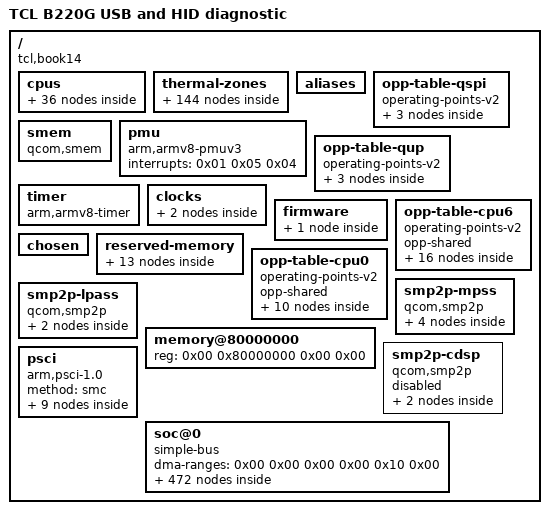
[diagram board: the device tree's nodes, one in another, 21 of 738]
/dts-v1/;

/ {
	model = "TCL B220G USB and HID diagnostic";
	compatible = "tcl,book14", "qcom,sc7180";
	interrupt-parent = <0x01>;
	#address-cells = <0x02>;
	#size-cells = <0x02>;

	cpus {
		#address-cells = <0x02>;
		#size-cells = <0x00>;

		cpu@600 {
			dynamic-power-coefficient = <0x1e0>;
			next-level-cache = <0x09>;
			clocks = <0xbb 0x01>;
			phandle = <0x11>;
			compatible = "qcom,kryo468";
			capacity-dmips-mhz = <0x400>;
			reg = <0x00 0x600>;
			device_type = "cpu";
			qcom,freq-domain = <0xbb 0x01>;
			enable-method = "psci";
			#cooling-cells = <0x02>;

			l2-cache {
				next-level-cache = <0x03>;
				phandle = <0x09>;
				compatible = "cache";
				cache-unified;
				cache-level = <0x02>;
			};
		};

		cpu@300 {
			dynamic-power-coefficient = <0x89>;
			next-level-cache = <0x06>;
			clocks = <0xbb 0x00>;
			phandle = <0x0e>;
			compatible = "qcom,kryo468";
			capacity-dmips-mhz = <0x19f>;
			reg = <0x00 0x300>;
			device_type = "cpu";
			qcom,freq-domain = <0xbb 0x00>;
			enable-method = "psci";
			#cooling-cells = <0x02>;

			l2-cache {
				next-level-cache = <0x03>;
				phandle = <0x06>;
				compatible = "cache";
				cache-unified;
				cache-level = <0x02>;
			};
		};

		cpu@0 {
			dynamic-power-coefficient = <0x89>;
			next-level-cache = <0x02>;
			clocks = <0xbb 0x00>;
			phandle = <0x0b>;
			compatible = "qcom,kryo468";
			capacity-dmips-mhz = <0x19f>;
			reg = <0x00 0x00>;
			device_type = "cpu";
			qcom,freq-domain = <0xbb 0x00>;
			enable-method = "psci";
			#cooling-cells = <0x02>;

			l2-cache {
				next-level-cache = <0x03>;
				phandle = <0x02>;
				compatible = "cache";
				cache-unified;
				cache-level = <0x02>;

				l3-cache {
					phandle = <0x03>;
					compatible = "cache";
					cache-unified;
					cache-level = <0x03>;
				};
			};
		};

		cpu@500 {
			dynamic-power-coefficient = <0x89>;
			next-level-cache = <0x08>;
			clocks = <0xbb 0x00>;
			phandle = <0x10>;
			compatible = "qcom,kryo468";
			capacity-dmips-mhz = <0x19f>;
			reg = <0x00 0x500>;
			device_type = "cpu";
			qcom,freq-domain = <0xbb 0x00>;
			enable-method = "psci";
			#cooling-cells = <0x02>;

			l2-cache {
				next-level-cache = <0x03>;
				phandle = <0x08>;
				compatible = "cache";
				cache-unified;
				cache-level = <0x02>;
			};
		};

		idle-states {
			entry-method = "psci";

			cpu-sleep-1-0 {
				min-residency-us = <0x89f>;
				exit-latency-us = <0x4dc>;
				phandle = <0x19>;
				compatible = "arm,idle-state";
				arm,psci-suspend-param = <0x40000003>;
				entry-latency-us = <0x20b>;
				local-timer-stop;
				idle-state-name = "big-power-down";
			};

			cpu-sleep-0-1 {
				min-residency-us = <0xfa1>;
				exit-latency-us = <0x393>;
				phandle = <0x18>;
				compatible = "arm,idle-state";
				arm,psci-suspend-param = <0x40000004>;
				entry-latency-us = <0x2be>;
				local-timer-stop;
				idle-state-name = "little-rail-power-down";
			};

			cpu-sleep-1-1 {
				min-residency-us = <0x15b3>;
				exit-latency-us = <0x73e>;
				phandle = <0x1a>;
				compatible = "arm,idle-state";
				arm,psci-suspend-param = <0x40000004>;
				entry-latency-us = <0x20e>;
				local-timer-stop;
				idle-state-name = "big-rail-power-down";
			};

			cpu-sleep-0-0 {
				min-residency-us = <0x6ee>;
				exit-latency-us = <0x385>;
				phandle = <0x17>;
				compatible = "arm,idle-state";
				arm,psci-suspend-param = <0x40000003>;
				entry-latency-us = <0x225>;
				local-timer-stop;
				idle-state-name = "little-power-down";
			};
		};

		cpu@400 {
			dynamic-power-coefficient = <0x89>;
			next-level-cache = <0x07>;
			clocks = <0xbb 0x00>;
			phandle = <0x0f>;
			compatible = "qcom,kryo468";
			capacity-dmips-mhz = <0x19f>;
			reg = <0x00 0x400>;
			device_type = "cpu";
			qcom,freq-domain = <0xbb 0x00>;
			enable-method = "psci";
			#cooling-cells = <0x02>;

			l2-cache {
				next-level-cache = <0x03>;
				phandle = <0x07>;
				compatible = "cache";
				cache-unified;
				cache-level = <0x02>;
			};
		};

		cpu@700 {
			dynamic-power-coefficient = <0x1e0>;
			next-level-cache = <0x0a>;
			clocks = <0xbb 0x01>;
			phandle = <0x12>;
			compatible = "qcom,kryo468";
			capacity-dmips-mhz = <0x400>;
			reg = <0x00 0x700>;
			device_type = "cpu";
			qcom,freq-domain = <0xbb 0x01>;
			enable-method = "psci";
			#cooling-cells = <0x02>;

			l2-cache {
				next-level-cache = <0x03>;
				phandle = <0x0a>;
				compatible = "cache";
				cache-unified;
				cache-level = <0x02>;
			};
		};

		cpu@200 {
			dynamic-power-coefficient = <0x89>;
			next-level-cache = <0x05>;
			clocks = <0xbb 0x00>;
			phandle = <0x0d>;
			compatible = "qcom,kryo468";
			capacity-dmips-mhz = <0x19f>;
			reg = <0x00 0x200>;
			device_type = "cpu";
			qcom,freq-domain = <0xbb 0x00>;
			enable-method = "psci";
			#cooling-cells = <0x02>;

			l2-cache {
				next-level-cache = <0x03>;
				phandle = <0x05>;
				compatible = "cache";
				cache-unified;
				cache-level = <0x02>;
			};
		};

		cpu@100 {
			dynamic-power-coefficient = <0x89>;
			next-level-cache = <0x04>;
			clocks = <0xbb 0x00>;
			phandle = <0x0c>;
			compatible = "qcom,kryo468";
			capacity-dmips-mhz = <0x19f>;
			reg = <0x00 0x100>;
			device_type = "cpu";
			qcom,freq-domain = <0xbb 0x00>;
			enable-method = "psci";
			#cooling-cells = <0x02>;

			l2-cache {
				next-level-cache = <0x03>;
				phandle = <0x04>;
				compatible = "cache";
				cache-unified;
				cache-level = <0x02>;
			};
		};

		cpu-map {

			cluster0 {

				core1 {
					cpu = <0x0c>;
				};

				core7 {
					cpu = <0x12>;
				};

				core4 {
					cpu = <0x0f>;
				};

				core3 {
					cpu = <0x0e>;
				};

				core2 {
					cpu = <0x0d>;
				};

				core5 {
					cpu = <0x10>;
				};

				core6 {
					cpu = <0x11>;
				};

				core0 {
					cpu = <0x0b>;
				};
			};
		};

		domain-idle-states {

			cluster-sleep-2 {
				min-residency-us = <0x2662>;
				exit-latency-us = <0x19a2>;
				phandle = <0x1d>;
				compatible = "domain-idle-state";
				arm,psci-suspend-param = <0x4100b244>;
				entry-latency-us = <0xcbf>;
			};

			cluster-sleep-1 {
				min-residency-us = <0x2113>;
				exit-latency-us = <0x11d2>;
				phandle = <0x1c>;
				compatible = "domain-idle-state";
				arm,psci-suspend-param = <0x41001244>;
				entry-latency-us = <0xe36>;
			};

			cluster-sleep-0 {
				min-residency-us = <0x17e6>;
				exit-latency-us = <0xbe8>;
				phandle = <0x1b>;
				compatible = "domain-idle-state";
				arm,psci-suspend-param = <0x41000044>;
				entry-latency-us = <0xac0>;
			};
		};
	};

	thermal-zones {

		cpu4-thermal {
			thermal-sensors = <0xc1 0x05>;
			polling-delay-passive = <0xfa>;
			sustainable-power = <0x41c>;

			cooling-maps {

				map0 {
					trip = <0xca>;
					cooling-device = <0x0b 0xffffffff 0xffffffff 0x0c 0xffffffff 0xffffffff 0x0d 0xffffffff 0xffffffff 0x0e 0xffffffff 0xffffffff 0x0f 0xffffffff 0xffffffff 0x10 0xffffffff 0xffffffff>;
				};

				map1 {
					trip = <0xcb>;
					cooling-device = <0x0b 0xffffffff 0xffffffff 0x0c 0xffffffff 0xffffffff 0x0d 0xffffffff 0xffffffff 0x0e 0xffffffff 0xffffffff 0x0f 0xffffffff 0xffffffff 0x10 0xffffffff 0xffffffff>;
				};
			};

			trips {

				trip-point1 {
					hysteresis = <0x7d0>;
					phandle = <0xcb>;
					temperature = <0x17318>;
					type = "passive";
				};

				trip-point0 {
					hysteresis = <0x7d0>;
					phandle = <0xca>;
					temperature = <0x15f90>;
					type = "passive";
				};

				cpu-crit {
					hysteresis = <0x3e8>;
					temperature = <0x1adb0>;
					type = "critical";
				};
			};
		};

		cpu5-thermal {
			thermal-sensors = <0xc1 0x06>;
			polling-delay-passive = <0xfa>;
			sustainable-power = <0x41c>;

			cooling-maps {

				map0 {
					trip = <0xcc>;
					cooling-device = <0x0b 0xffffffff 0xffffffff 0x0c 0xffffffff 0xffffffff 0x0d 0xffffffff 0xffffffff 0x0e 0xffffffff 0xffffffff 0x0f 0xffffffff 0xffffffff 0x10 0xffffffff 0xffffffff>;
				};

				map1 {
					trip = <0xcd>;
					cooling-device = <0x0b 0xffffffff 0xffffffff 0x0c 0xffffffff 0xffffffff 0x0d 0xffffffff 0xffffffff 0x0e 0xffffffff 0xffffffff 0x0f 0xffffffff 0xffffffff 0x10 0xffffffff 0xffffffff>;
				};
			};

			trips {

				trip-point1 {
					hysteresis = <0x7d0>;
					phandle = <0xcd>;
					temperature = <0x17318>;
					type = "passive";
				};

				trip-point0 {
					hysteresis = <0x7d0>;
					phandle = <0xcc>;
					temperature = <0x15f90>;
					type = "passive";
				};

				cpu-crit {
					hysteresis = <0x3e8>;
					temperature = <0x1adb0>;
					type = "critical";
				};
			};
		};

		cpu9-thermal {
			thermal-sensors = <0xc1 0x0c>;
			polling-delay-passive = <0xfa>;
			sustainable-power = <0x591>;

			cooling-maps {

				map0 {
					trip = <0xd4>;
					cooling-device = <0x11 0xffffffff 0xffffffff 0x12 0xffffffff 0xffffffff>;
				};

				map1 {
					trip = <0xd5>;
					cooling-device = <0x11 0xffffffff 0xffffffff 0x12 0xffffffff 0xffffffff>;
				};
			};

			trips {

				trip-point1 {
					hysteresis = <0x7d0>;
					phandle = <0xd5>;
					temperature = <0x17318>;
					type = "passive";
				};

				trip-point0 {
					hysteresis = <0x7d0>;
					phandle = <0xd4>;
					temperature = <0x15f90>;
					type = "passive";
				};

				cpu-crit {
					hysteresis = <0x3e8>;
					temperature = <0x1adb0>;
					type = "critical";
				};
			};
		};

		cpu2-thermal {
			thermal-sensors = <0xc1 0x03>;
			polling-delay-passive = <0xfa>;
			sustainable-power = <0x41c>;

			cooling-maps {

				map0 {
					trip = <0xc6>;
					cooling-device = <0x0b 0xffffffff 0xffffffff 0x0c 0xffffffff 0xffffffff 0x0d 0xffffffff 0xffffffff 0x0e 0xffffffff 0xffffffff 0x0f 0xffffffff 0xffffffff 0x10 0xffffffff 0xffffffff>;
				};

				map1 {
					trip = <0xc7>;
					cooling-device = <0x0b 0xffffffff 0xffffffff 0x0c 0xffffffff 0xffffffff 0x0d 0xffffffff 0xffffffff 0x0e 0xffffffff 0xffffffff 0x0f 0xffffffff 0xffffffff 0x10 0xffffffff 0xffffffff>;
				};
			};

			trips {

				trip-point1 {
					hysteresis = <0x7d0>;
					phandle = <0xc7>;
					temperature = <0x17318>;
					type = "passive";
				};

				trip-point0 {
					hysteresis = <0x7d0>;
					phandle = <0xc6>;
					temperature = <0x15f90>;
					type = "passive";
				};

				cpu-crit {
					hysteresis = <0x3e8>;
					temperature = <0x1adb0>;
					type = "critical";
				};
			};
		};

		cpu1-thermal {
			thermal-sensors = <0xc1 0x02>;
			polling-delay-passive = <0xfa>;
			sustainable-power = <0x41c>;

			cooling-maps {

				map0 {
					trip = <0xc4>;
					cooling-device = <0x0b 0xffffffff 0xffffffff 0x0c 0xffffffff 0xffffffff 0x0d 0xffffffff 0xffffffff 0x0e 0xffffffff 0xffffffff 0x0f 0xffffffff 0xffffffff 0x10 0xffffffff 0xffffffff>;
				};

				map1 {
					trip = <0xc5>;
					cooling-device = <0x0b 0xffffffff 0xffffffff 0x0c 0xffffffff 0xffffffff 0x0d 0xffffffff 0xffffffff 0x0e 0xffffffff 0xffffffff 0x0f 0xffffffff 0xffffffff 0x10 0xffffffff 0xffffffff>;
				};
			};

			trips {

				trip-point1 {
					hysteresis = <0x7d0>;
					phandle = <0xc5>;
					temperature = <0x17318>;
					type = "passive";
				};

				trip-point0 {
					hysteresis = <0x7d0>;
					phandle = <0xc4>;
					temperature = <0x15f90>;
					type = "passive";
				};

				cpu-crit {
					hysteresis = <0x3e8>;
					temperature = <0x1adb0>;
					type = "critical";
				};
			};
		};

		mdm-core-thermal {
			thermal-sensors = <0xd9 0x06>;
			polling-delay-passive = <0xfa>;

			trips {

				trip-point0 {
					hysteresis = <0x7d0>;
					temperature = <0x15f90>;
					type = "hot";
				};

				mdm-crit {
					hysteresis = <0x7d0>;
					temperature = <0x1adb0>;
					type = "critical";
				};
			};
		};

		gpuss0-thermal {
			thermal-sensors = <0xc1 0x0d>;
			polling-delay-passive = <0xfa>;

			cooling-maps {

				map0 {
					trip = <0xd6>;
					cooling-device = <0xd7 0xffffffff 0xffffffff>;
				};
			};

			trips {

				gpuss0-crit {
					hysteresis = <0x7d0>;
					temperature = <0x1adb0>;
					type = "critical";
				};

				trip-point0 {
					hysteresis = <0x7d0>;
					phandle = <0xd6>;
					temperature = <0x17318>;
					type = "passive";
				};
			};
		};

		cpu3-thermal {
			thermal-sensors = <0xc1 0x04>;
			polling-delay-passive = <0xfa>;
			sustainable-power = <0x41c>;

			cooling-maps {

				map0 {
					trip = <0xc8>;
					cooling-device = <0x0b 0xffffffff 0xffffffff 0x0c 0xffffffff 0xffffffff 0x0d 0xffffffff 0xffffffff 0x0e 0xffffffff 0xffffffff 0x0f 0xffffffff 0xffffffff 0x10 0xffffffff 0xffffffff>;
				};

				map1 {
					trip = <0xc9>;
					cooling-device = <0x0b 0xffffffff 0xffffffff 0x0c 0xffffffff 0xffffffff 0x0d 0xffffffff 0xffffffff 0x0e 0xffffffff 0xffffffff 0x0f 0xffffffff 0xffffffff 0x10 0xffffffff 0xffffffff>;
				};
			};

			trips {

				trip-point1 {
					hysteresis = <0x7d0>;
					phandle = <0xc9>;
					temperature = <0x17318>;
					type = "passive";
				};

				trip-point0 {
					hysteresis = <0x7d0>;
					phandle = <0xc8>;
					temperature = <0x15f90>;
					type = "passive";
				};

				cpu-crit {
					hysteresis = <0x3e8>;
					temperature = <0x1adb0>;
					type = "critical";
				};
			};
		};

		video-thermal {
			thermal-sensors = <0xd9 0x09>;
			polling-delay-passive = <0xfa>;

			trips {

				trip-point0 {
					hysteresis = <0x7d0>;
					temperature = <0x15f90>;
					type = "hot";
				};

				video-crit {
					hysteresis = <0x7d0>;
					temperature = <0x1adb0>;
					type = "critical";
				};
			};
		};

		npu-thermal {
			thermal-sensors = <0xd9 0x08>;
			polling-delay-passive = <0xfa>;

			trips {

				npu-crit {
					hysteresis = <0x7d0>;
					temperature = <0x1adb0>;
					type = "critical";
				};

				trip-point0 {
					hysteresis = <0x7d0>;
					temperature = <0x15f90>;
					type = "hot";
				};
			};
		};

		cwlan-thermal {
			thermal-sensors = <0xd9 0x01>;
			polling-delay-passive = <0xfa>;

			trips {

				cwlan-crit {
					hysteresis = <0x7d0>;
					temperature = <0x1adb0>;
					type = "critical";
				};

				trip-point0 {
					hysteresis = <0x7d0>;
					temperature = <0x15f90>;
					type = "hot";
				};
			};
		};

		cpuss0-thermal {
			thermal-sensors = <0xc1 0x07>;
			polling-delay-passive = <0xfa>;

			trips {

				cluster0-crit {
					hysteresis = <0x7d0>;
					temperature = <0x1adb0>;
					type = "critical";
				};

				trip-point0 {
					hysteresis = <0x7d0>;
					temperature = <0x15f90>;
					type = "hot";
				};
			};
		};

		audio-thermal {
			thermal-sensors = <0xd9 0x02>;
			polling-delay-passive = <0xfa>;

			trips {

				audio-crit {
					hysteresis = <0x7d0>;
					temperature = <0x1adb0>;
					type = "critical";
				};

				trip-point0 {
					hysteresis = <0x7d0>;
					temperature = <0x15f90>;
					type = "hot";
				};
			};
		};

		camera-thermal {
			thermal-sensors = <0xd9 0x05>;
			polling-delay-passive = <0xfa>;

			trips {

				camera-crit {
					hysteresis = <0x7d0>;
					temperature = <0x1adb0>;
					type = "critical";
				};

				trip-point0 {
					hysteresis = <0x7d0>;
					temperature = <0x15f90>;
					type = "hot";
				};
			};
		};

		aoss1-thermal {
			thermal-sensors = <0xd9 0x00>;
			polling-delay-passive = <0xfa>;

			trips {

				aoss1-crit {
					hysteresis = <0x7d0>;
					temperature = <0x1adb0>;
					type = "critical";
				};

				trip-point0 {
					hysteresis = <0x7d0>;
					temperature = <0x15f90>;
					type = "hot";
				};
			};
		};

		cpu8-thermal {
			thermal-sensors = <0xc1 0x0b>;
			polling-delay-passive = <0xfa>;
			sustainable-power = <0x591>;

			cooling-maps {

				map0 {
					trip = <0xd2>;
					cooling-device = <0x11 0xffffffff 0xffffffff 0x12 0xffffffff 0xffffffff>;
				};

				map1 {
					trip = <0xd3>;
					cooling-device = <0x11 0xffffffff 0xffffffff 0x12 0xffffffff 0xffffffff>;
				};
			};

			trips {

				trip-point1 {
					hysteresis = <0x7d0>;
					phandle = <0xd3>;
					temperature = <0x17318>;
					type = "passive";
				};

				trip-point0 {
					hysteresis = <0x7d0>;
					phandle = <0xd2>;
					temperature = <0x15f90>;
					type = "passive";
				};

				cpu-crit {
					hysteresis = <0x3e8>;
					temperature = <0x1adb0>;
					type = "critical";
				};
			};
		};

		ddr-thermal {
			thermal-sensors = <0xd9 0x03>;
			polling-delay-passive = <0xfa>;

			trips {

				trip-point0 {
					hysteresis = <0x7d0>;
					temperature = <0x15f90>;
					type = "hot";
				};

				ddr-crit {
					hysteresis = <0x7d0>;
					temperature = <0x1adb0>;
					type = "critical";
				};
			};
		};

		gpuss1-thermal {
			thermal-sensors = <0xc1 0x0e>;
			polling-delay-passive = <0xfa>;

			cooling-maps {

				map0 {
					trip = <0xd8>;
					cooling-device = <0xd7 0xffffffff 0xffffffff>;
				};
			};

			trips {

				gpuss1-crit {
					hysteresis = <0x7d0>;
					temperature = <0x1adb0>;
					type = "critical";
				};

				trip-point0 {
					hysteresis = <0x7d0>;
					phandle = <0xd8>;
					temperature = <0x17318>;
					type = "passive";
				};
			};
		};

		cpu7-thermal {
			thermal-sensors = <0xc1 0x0a>;
			polling-delay-passive = <0xfa>;
			sustainable-power = <0x591>;

			cooling-maps {

				map0 {
					trip = <0xd0>;
					cooling-device = <0x11 0xffffffff 0xffffffff 0x12 0xffffffff 0xffffffff>;
				};

				map1 {
					trip = <0xd1>;
					cooling-device = <0x11 0xffffffff 0xffffffff 0x12 0xffffffff 0xffffffff>;
				};
			};

			trips {

				trip-point1 {
					hysteresis = <0x7d0>;
					phandle = <0xd1>;
					temperature = <0x17318>;
					type = "passive";
				};

				trip-point0 {
					hysteresis = <0x7d0>;
					phandle = <0xd0>;
					temperature = <0x15f90>;
					type = "passive";
				};

				cpu-crit {
					hysteresis = <0x3e8>;
					temperature = <0x1adb0>;
					type = "critical";
				};
			};
		};

		cpuss1-thermal {
			thermal-sensors = <0xc1 0x08>;
			polling-delay-passive = <0xfa>;

			trips {

				cluster0-crit {
					hysteresis = <0x7d0>;
					temperature = <0x1adb0>;
					type = "critical";
				};

				trip-point0 {
					hysteresis = <0x7d0>;
					temperature = <0x15f90>;
					type = "hot";
				};
			};
		};

		cpu0-thermal {
			thermal-sensors = <0xc1 0x01>;
			polling-delay-passive = <0xfa>;
			sustainable-power = <0x41c>;

			cooling-maps {

				map0 {
					trip = <0xc2>;
					cooling-device = <0x0b 0xffffffff 0xffffffff 0x0c 0xffffffff 0xffffffff 0x0d 0xffffffff 0xffffffff 0x0e 0xffffffff 0xffffffff 0x0f 0xffffffff 0xffffffff 0x10 0xffffffff 0xffffffff>;
				};

				map1 {
					trip = <0xc3>;
					cooling-device = <0x0b 0xffffffff 0xffffffff 0x0c 0xffffffff 0xffffffff 0x0d 0xffffffff 0xffffffff 0x0e 0xffffffff 0xffffffff 0x0f 0xffffffff 0xffffffff 0x10 0xffffffff 0xffffffff>;
				};
			};

			trips {

				trip-point1 {
					hysteresis = <0x7d0>;
					phandle = <0xc3>;
					temperature = <0x17318>;
					type = "passive";
				};

				trip-point0 {
					hysteresis = <0x7d0>;
					phandle = <0xc2>;
					temperature = <0x15f90>;
					type = "passive";
				};

				cpu-crit {
					hysteresis = <0x3e8>;
					temperature = <0x1adb0>;
					type = "critical";
				};
			};
		};

		aoss0-thermal {
			thermal-sensors = <0xc1 0x00>;
			polling-delay-passive = <0xfa>;

			trips {

				aoss0-crit {
					hysteresis = <0x7d0>;
					temperature = <0x1adb0>;
					type = "critical";
				};

				trip-point0 {
					hysteresis = <0x7d0>;
					temperature = <0x15f90>;
					type = "hot";
				};
			};
		};

		cpu6-thermal {
			thermal-sensors = <0xc1 0x09>;
			polling-delay-passive = <0xfa>;
			sustainable-power = <0x591>;

			cooling-maps {

				map0 {
					trip = <0xce>;
					cooling-device = <0x11 0xffffffff 0xffffffff 0x12 0xffffffff 0xffffffff>;
				};

				map1 {
					trip = <0xcf>;
					cooling-device = <0x11 0xffffffff 0xffffffff 0x12 0xffffffff 0xffffffff>;
				};
			};

			trips {

				trip-point1 {
					hysteresis = <0x7d0>;
					phandle = <0xcf>;
					temperature = <0x17318>;
					type = "passive";
				};

				trip-point0 {
					hysteresis = <0x7d0>;
					phandle = <0xce>;
					temperature = <0x15f90>;
					type = "passive";
				};

				cpu-crit {
					hysteresis = <0x3e8>;
					temperature = <0x1adb0>;
					type = "critical";
				};
			};
		};

		mdm-dsp-thermal {
			thermal-sensors = <0xd9 0x07>;
			polling-delay-passive = <0xfa>;

			trips {

				trip-point0 {
					hysteresis = <0x7d0>;
					temperature = <0x15f90>;
					type = "hot";
				};

				mdm-dsp-crit {
					hysteresis = <0x7d0>;
					temperature = <0x1adb0>;
					type = "critical";
				};
			};
		};

		q6-hvx-thermal {
			thermal-sensors = <0xd9 0x04>;
			polling-delay-passive = <0xfa>;

			trips {

				trip-point0 {
					hysteresis = <0x7d0>;
					temperature = <0x15f90>;
					type = "hot";
				};

				q6-hvx-crit {
					hysteresis = <0x7d0>;
					temperature = <0x1adb0>;
					type = "critical";
				};
			};
		};
	};

	aliases {
		spi11 = "/soc@0/geniqup@ac0000/spi@a94000";
		spi6 = "/soc@0/geniqup@ac0000/spi@a80000";
		spi0 = "/soc@0/geniqup@8c0000/spi@880000";
		i2c1 = "/soc@0/geniqup@8c0000/i2c@884000";
		spi8 = "/soc@0/geniqup@ac0000/spi@a88000";
		i2c5 = "/soc@0/geniqup@8c0000/i2c@894000";
		mmc1 = "/soc@0/mmc@7c4000";
		spi10 = "/soc@0/geniqup@ac0000/spi@a90000";
		spi3 = "/soc@0/geniqup@8c0000/spi@88c000";
		i2c8 = "/soc@0/geniqup@ac0000/i2c@a88000";
		i2c9 = "/soc@0/geniqup@ac0000/i2c@a8c000";
		spi5 = "/soc@0/geniqup@8c0000/spi@894000";
		mmc2 = "/soc@0/mmc@8804000";
		spi1 = "/soc@0/geniqup@8c0000/spi@884000";
		i2c7 = "/soc@0/geniqup@ac0000/i2c@a84000";
		i2c3 = "/soc@0/geniqup@8c0000/i2c@88c000";
		i2c4 = "/soc@0/geniqup@8c0000/i2c@890000";
		i2c10 = "/soc@0/geniqup@ac0000/i2c@a90000";
		i2c11 = "/soc@0/geniqup@ac0000/i2c@a94000";
		i2c2 = "/soc@0/geniqup@8c0000/i2c@888000";
		i2c0 = "/soc@0/geniqup@8c0000/i2c@880000";
		i2c6 = "/soc@0/geniqup@ac0000/i2c@a80000";
	};

	opp-table-qspi {
		phandle = <0x92>;
		compatible = "operating-points-v2";

		opp-75000000 {
			opp-hz = <0x00 0x47868c0>;
			required-opps = <0x13>;
		};

		opp-300000000 {
			opp-hz = <0x00 0x11e1a300>;
			required-opps = <0x15>;
		};

		opp-150000000 {
			opp-hz = <0x00 0x8f0d180>;
			required-opps = <0x14>;
		};
	};

	smem {
		compatible = "qcom,smem";
		memory-region = <0x1e>;
		hwlocks = <0x1f 0x03>;
	};

	pmu {
		compatible = "arm,armv8-pmuv3";
		interrupts = <0x01 0x05 0x04>;
	};

	opp-table-qup {
		phandle = <0x2f>;
		compatible = "operating-points-v2";

		opp-75000000 {
			opp-hz = <0x00 0x47868c0>;
			required-opps = <0x13>;
		};

		opp-100000000 {
			opp-hz = <0x00 0x5f5e100>;
			required-opps = <0x14>;
		};

		opp-128000000 {
			opp-hz = <0x00 0x7a12000>;
			required-opps = <0x15>;
		};
	};

	timer {
		compatible = "arm,armv8-timer";
		interrupts = <0x01 0x01 0x08 0x01 0x02 0x08 0x01 0x03 0x08 0x01 0x00 0x08>;
	};

	clocks {

		xo-board {
			phandle = <0xad>;
			compatible = "fixed-clock";
			#clock-cells = <0x00>;
			clock-frequency = <0x249f000>;
		};

		sleep-clk {
			phandle = <0x22>;
			compatible = "fixed-clock";
			#clock-cells = <0x00>;
			clock-frequency = <0x7ffc>;
		};
	};

	firmware {

		scm {
			compatible = "qcom,scm-sc7180", "qcom,scm";
		};
	};

	opp-table-cpu6 {
		opp-shared;
		compatible = "operating-points-v2";

		opp-652800000 {
			opp-hz = <0x00 0x26e8f000>;
			opp-peak-kBps = <0x2162e0 0x87f000>;
		};

		opp-979200000 {
			opp-hz = <0x00 0x3a5d6800>;
			opp-peak-kBps = <0x2162e0 0x87f000>;
		};

		opp-825600000 {
			opp-hz = <0x00 0x3135a800>;
			opp-peak-kBps = <0x2162e0 0x87f000>;
		};

		opp-2323200000 {
			opp-hz = <0x00 0x8a793800>;
			opp-peak-kBps = <0x6e1b80 0x1563000>;
		};

		opp-2112000000 {
			opp-hz = <0x00 0x7de29000>;
			opp-peak-kBps = <0x5ee8e0 0x1563000>;
		};

		opp-1996800000 {
			opp-hz = <0x00 0x7704c000>;
			opp-peak-kBps = <0x5ee8e0 0x1563000>;
		};

		opp-1555200000 {
			opp-hz = <0x00 0x5cb27800>;
			opp-peak-kBps = <0x3e12a0 0xe5b000>;
		};

		opp-2553600000 {
			opp-hz = <0x00 0x9834d800>;
			opp-peak-kBps = <0x823020 0x1644000>;
		};

		opp-300000000 {
			opp-hz = <0x00 0x11e1a300>;
			opp-peak-kBps = <0x2162e0 0x87f000>;
		};

		opp-1113600000 {
			opp-hz = <0x00 0x42603000>;
			opp-peak-kBps = <0x2162e0 0x87f000>;
		};

		opp-2400000000 {
			opp-hz = <0x00 0x8f0d1800>;
			opp-peak-kBps = <0x823020 0x1644000>;
		};

		opp-1900800000 {
			opp-hz = <0x00 0x714be800>;
			opp-peak-kBps = <0x5ee8e0 0x1563000>;
		};

		opp-1267200000 {
			opp-hz = <0x00 0x4b87f000>;
			opp-peak-kBps = <0x3e12a0 0xc4e000>;
		};

		opp-1708800000 {
			opp-hz = <0x00 0x65da3800>;
			opp-peak-kBps = <0x5ee8e0 0x1275000>;
		};

		opp-1843200000 {
			opp-hz = <0x00 0x6ddd0000>;
			opp-peak-kBps = <0x5ee8e0 0x1275000>;
		};

		opp-2208000000 {
			opp-hz = <0x00 0x839b6800>;
			opp-peak-kBps = <0x6e1b80 0x1563000>;
		};
	};

	chosen {
		linux,uefi-mmap-size = <0xa50>;
		linux,uefi-mmap-desc-size = <0x30>;
		linux,uefi-mmap-start = <0x00 0xfffb2040>;
		bootargs = "BOOT_IMAGE=/tcl-memdiag/Image console=tty0 earlycon=efifb efi=novamap,noruntime,debug clk_ignore_unused pd_ignore_unused regulator_ignore_unused maxcpus=8 cpuidle.off=1 cpufreq.default_governor=schedutil nokaslr loglevel=7 panic=0 rdinit=/init modprobe.blacklist=msm,tcl_lt8911_handoff,venus_core,venus_dec,venus_enc tcl.kms=early tcl.adsp=probe tcl.memdiag=1";
		linux,uefi-mmap-desc-ver = <0x01>;
		linux,uefi-system-table = <0x00 0xffec1018>;
	};

	reserved-memory {
		#address-cells = <0x02>;
		#size-cells = <0x02>;
		ranges;

		memory@80800000 {
			no-map;
			reg = <0x00 0x80800000 0x00 0x20000>;
		};

		memory@8b700000 {
			no-map;
			reg = <0x00 0x8b700000 0x00 0x10000>;
		};

		memory@80820000 {
			no-map;
			compatible = "qcom,cmd-db";
			reg = <0x00 0x80820000 0x00 0x20000>;
		};

		memory@80b00000 {
			no-map;
			reg = <0x00 0x80b00000 0x00 0x3900000>;
		};

		venus@85b00000 {
			no-map;
			phandle = <0xbe>;
			reg = <0x00 0x85b00000 0x00 0x500000>;
		};

		adsp@90b00000 {
			no-map;
			phandle = <0xc0>;
			reg = <0x00 0x90b00000 0x00 0x2800000>;
		};

		mpss@86000000 {
			no-map;
			phandle = <0x65>;
			reg = <0x00 0x86000000 0x00 0x2000000>;
		};

		memory@80000000 {
			no-map;
			reg = <0x00 0x80000000 0x00 0x600000>;
		};

		wlan@93900000 {
			no-map;
			phandle = <0xaf>;
			reg = <0x00 0x93900000 0x00 0x200000>;
		};

		memory@80900000 {
			no-map;
			phandle = <0x1e>;
			reg = <0x00 0x80900000 0x00 0x200000>;
		};

		memory@808ff000 {
			no-map;
			reg = <0x00 0x808ff000 0x00 0x1000>;
		};

		zap-shader@80840000 {
			no-map;
			phandle = <0xbd>;
			reg = <0x00 0x80840000 0x00 0x2000>;
		};

		memory@80600000 {
			no-map;
			qcom,client-id = <0x01>;
			compatible = "qcom,rmtfs-mem";
			reg = <0x00 0x80600000 0x00 0x200000>;
			status = "okay";
		};
	};

	opp-table-cpu0 {
		opp-shared;
		compatible = "operating-points-v2";

		opp-1017600000 {
			opp-hz = <0x00 0x3ca75800>;
			opp-peak-kBps = <0x1b86e0 0x87f000>;
		};

		opp-576000000 {
			opp-hz = <0x00 0x22551000>;
			opp-peak-kBps = <0x124f80 0x493e00>;
		};

		opp-768000000 {
			opp-hz = <0x00 0x2dc6c000>;
			opp-peak-kBps = <0x124f80 0x493e00>;
		};

		opp-1324800000 {
			opp-hz = <0x00 0x4ef6d800>;
			opp-peak-kBps = <0x2162e0 0xc4e000>;
		};

		opp-300000000 {
			opp-hz = <0x00 0x11e1a300>;
			opp-peak-kBps = <0x124f80 0x493e00>;
		};

		opp-1804800000 {
			opp-hz = <0x00 0x6b931000>;
			opp-peak-kBps = <0x3e12a0 0x1563000>;
		};

		opp-1708800000 {
			opp-hz = <0x00 0x65da3800>;
			opp-peak-kBps = <0x2ee000 0xe5b000>;
		};

		opp-1516800000 {
			opp-hz = <0x00 0x5a688800>;
			opp-peak-kBps = <0x2ee000 0xe5b000>;
		};

		opp-1612800000 {
			opp-hz = <0x00 0x60216000>;
			opp-peak-kBps = <0x2ee000 0xe5b000>;
		};

		opp-1248000000 {
			opp-hz = <0x00 0x4a62f800>;
			opp-peak-kBps = <0x2162e0 0xc4e000>;
		};
	};

	smp2p-mpss {
		qcom,remote-pid = <0x01>;
		mboxes = <0x20 0x0e>;
		compatible = "qcom,smp2p";
		interrupts = <0x00 0x1c3 0x01>;
		status = "okay";
		qcom,local-pid = <0x00>;
		qcom,smem = <0x1b3 0x1ac>;

		ipa-ap-to-modem {
			qcom,entry-name = "ipa";
			phandle = <0x62>;
			#qcom,smem-state-cells = <0x01>;
		};

		slave-kernel {
			qcom,entry-name = "slave-kernel";
			interrupt-controller;
			phandle = <0x64>;
			#interrupt-cells = <0x02>;
		};

		master-kernel {
			qcom,entry-name = "master-kernel";
			phandle = <0x66>;
			#qcom,smem-state-cells = <0x01>;
		};

		ipa-modem-to-ap {
			qcom,entry-name = "ipa";
			interrupt-controller;
			phandle = <0x5f>;
			#interrupt-cells = <0x02>;
		};
	};

	smp2p-lpass {
		qcom,remote-pid = <0x02>;
		mboxes = <0x20 0x0a>;
		compatible = "qcom,smp2p";
		interrupts = <0x00 0x9e 0x01>;
		status = "okay";
		qcom,local-pid = <0x00>;
		qcom,smem = <0x1bb 0x1ad>;

		slave-kernel {
			qcom,entry-name = "slave-kernel";
			interrupt-controller;
			phandle = <0xb5>;
			#interrupt-cells = <0x02>;
		};

		master-kernel {
			qcom,entry-name = "master-kernel";
			phandle = <0xb6>;
			#qcom,smem-state-cells = <0x01>;
		};
	};

	memory@80000000 {
		reg = <0x00 0x80000000 0x00 0x00>;
		device_type = "memory";
	};

	smp2p-cdsp {
		qcom,remote-pid = <0x05>;
		mboxes = <0x20 0x06>;
		compatible = "qcom,smp2p";
		interrupts = <0x00 0x240 0x01>;
		status = "disabled";
		qcom,local-pid = <0x00>;
		qcom,smem = <0x5e 0x1b0>;

		slave-kernel {
			qcom,entry-name = "slave-kernel";
			interrupt-controller;
			#interrupt-cells = <0x02>;
		};

		master-kernel {
			qcom,entry-name = "master-kernel";
			#qcom,smem-state-cells = <0x01>;
		};
	};

	psci {
		compatible = "arm,psci-1.0";
		method = "smc";

		power-domain-cpu2 {
			#power-domain-cells = <0x00>;
			power-domains = <0x16>;
			domain-idle-states = <0x17 0x18>;
		};

		power-domain-cluster {
			phandle = <0x16>;
			#power-domain-cells = <0x00>;
			domain-idle-states = <0x1b 0x1c 0x1d>;
		};

		power-domain-cpu7 {
			#power-domain-cells = <0x00>;
			power-domains = <0x16>;
			domain-idle-states = <0x19 0x1a>;
		};

		power-domain-cpu3 {
			#power-domain-cells = <0x00>;
			power-domains = <0x16>;
			domain-idle-states = <0x17 0x18>;
		};

		power-domain-cpu5 {
			#power-domain-cells = <0x00>;
			power-domains = <0x16>;
			domain-idle-states = <0x17 0x18>;
		};

		power-domain-cpu0 {
			#power-domain-cells = <0x00>;
			power-domains = <0x16>;
			domain-idle-states = <0x17 0x18>;
		};

		power-domain-cpu4 {
			#power-domain-cells = <0x00>;
			power-domains = <0x16>;
			domain-idle-states = <0x17 0x18>;
		};

		power-domain-cpu1 {
			#power-domain-cells = <0x00>;
			power-domains = <0x16>;
			domain-idle-states = <0x17 0x18>;
		};

		power-domain-cpu6 {
			#power-domain-cells = <0x00>;
			power-domains = <0x16>;
			domain-idle-states = <0x19 0x1a>;
		};
	};

	soc@0 {
		compatible = "simple-bus";
		#address-cells = <0x02>;
		#size-cells = <0x02>;
		dma-ranges = <0x00 0x00 0x00 0x00 0x10 0x00>;
		ranges = <0x00 0x00 0x00 0x00 0x10 0x00>;

		geniqup@8c0000 {
			iommus = <0x25 0x43 0x00>;
			clocks = <0x24 0x54 0x24 0x55>;
			compatible = "qcom,geni-se-qup";
			reg = <0x00 0x8c0000 0x00 0x6000>;
			clock-names = "m-ahb", "s-ahb";
			status = "okay";
			#address-cells = <0x02>;
			#size-cells = <0x02>;
			ranges;

			spi@88c000 {
				operating-points-v2 = <0x2f>;
				interconnect-names = "qup-core", "qup-config";
				clocks = <0x24 0x40>;
				pinctrl-names = "default";
				pinctrl-0 = <0x38 0x39>;
				compatible = "qcom,geni-spi";
				reg = <0x00 0x88c000 0x00 0x4000>;
				clock-names = "se";
				interrupts = <0x00 0x25c 0x04>;
				status = "disabled";
				#address-cells = <0x01>;
				#size-cells = <0x00>;
				power-domains = <0x23 0x00>;
				interconnects = <0x2c 0x00 0x00 0x2c 0x02 0x00 0x28 0x00 0x00 0x29 0x26 0x00>;
			};

			serial@888000 {
				operating-points-v2 = <0x2f>;
				interconnect-names = "qup-core", "qup-config";
				clocks = <0x24 0x3e>;
				pinctrl-names = "default";
				pinctrl-0 = <0x36>;
				compatible = "qcom,geni-uart";
				reg = <0x00 0x888000 0x00 0x4000>;
				clock-names = "se";
				interrupts = <0x00 0x25b 0x04>;
				status = "disabled";
				power-domains = <0x23 0x00>;
				interconnects = <0x2c 0x00 0x00 0x2c 0x02 0x00 0x28 0x00 0x00 0x29 0x26 0x00>;
			};

			serial@890000 {
				operating-points-v2 = <0x2f>;
				interconnect-names = "qup-core", "qup-config";
				clocks = <0x24 0x42>;
				pinctrl-names = "default";
				pinctrl-0 = <0x41>;
				compatible = "qcom,geni-uart";
				reg = <0x00 0x890000 0x00 0x4000>;
				clock-names = "se";
				interrupts = <0x00 0x25d 0x04>;
				status = "disabled";
				power-domains = <0x23 0x00>;
				interconnects = <0x2c 0x00 0x00 0x2c 0x02 0x00 0x28 0x00 0x00 0x29 0x26 0x00>;
			};

			i2c@894000 {
				interconnect-names = "qup-core", "qup-config", "qup-memory";
				clocks = <0x24 0x44>;
				required-opps = <0x13>;
				pinctrl-names = "default";
				pinctrl-0 = <0x42>;
				compatible = "qcom,geni-i2c";
				reg = <0x00 0x894000 0x00 0x4000>;
				clock-names = "se";
				interrupts = <0x00 0x25e 0x04>;
				status = "disabled";
				#address-cells = <0x01>;
				#size-cells = <0x00>;
				power-domains = <0x23 0x00>;
				interconnects = <0x2c 0x00 0x00 0x2c 0x02 0x00 0x28 0x00 0x00 0x29 0x26 0x00 0x26 0x02 0x00 0x27 0x01 0x00>;
			};

			i2c@88c000 {
				interconnect-names = "qup-core", "qup-config", "qup-memory";
				clocks = <0x24 0x40>;
				required-opps = <0x13>;
				pinctrl-names = "default";
				pinctrl-0 = <0x37>;
				compatible = "qcom,geni-i2c";
				reg = <0x00 0x88c000 0x00 0x4000>;
				clock-names = "se";
				interrupts = <0x00 0x25c 0x04>;
				status = "disabled";
				#address-cells = <0x01>;
				#size-cells = <0x00>;
				power-domains = <0x23 0x00>;
				interconnects = <0x2c 0x00 0x00 0x2c 0x02 0x00 0x28 0x00 0x00 0x29 0x26 0x00 0x26 0x02 0x00 0x27 0x01 0x00>;
			};

			i2c@888000 {
				interconnect-names = "qup-core", "qup-config", "qup-memory";
				clocks = <0x24 0x3e>;
				required-opps = <0x13>;
				pinctrl-names = "default";
				pinctrl-0 = <0x35>;
				compatible = "qcom,geni-i2c";
				reg = <0x00 0x888000 0x00 0x4000>;
				clock-names = "se";
				interrupts = <0x00 0x25b 0x04>;
				status = "okay";
				#address-cells = <0x01>;
				clock-frequency = <0x61a80>;
				#size-cells = <0x00>;
				power-domains = <0x23 0x00>;
				interconnects = <0x2c 0x00 0x00 0x2c 0x02 0x00 0x28 0x00 0x00 0x29 0x26 0x00 0x26 0x02 0x00 0x27 0x01 0x00>;
			};

			spi@894000 {
				operating-points-v2 = <0x2f>;
				interconnect-names = "qup-core", "qup-config";
				clocks = <0x24 0x44>;
				pinctrl-names = "default";
				pinctrl-0 = <0x43 0x44>;
				compatible = "qcom,geni-spi";
				reg = <0x00 0x894000 0x00 0x4000>;
				clock-names = "se";
				interrupts = <0x00 0x25e 0x04>;
				status = "disabled";
				#address-cells = <0x01>;
				#size-cells = <0x00>;
				power-domains = <0x23 0x00>;
				interconnects = <0x2c 0x00 0x00 0x2c 0x02 0x00 0x28 0x00 0x00 0x29 0x26 0x00>;
			};

			serial@884000 {
				operating-points-v2 = <0x2f>;
				interconnect-names = "qup-core", "qup-config";
				clocks = <0x24 0x3c>;
				pinctrl-names = "default";
				pinctrl-0 = <0x34>;
				compatible = "qcom,geni-uart";
				reg = <0x00 0x884000 0x00 0x4000>;
				clock-names = "se";
				interrupts = <0x00 0x25a 0x04>;
				status = "disabled";
				power-domains = <0x23 0x00>;
				interconnects = <0x2c 0x00 0x00 0x2c 0x02 0x00 0x28 0x00 0x00 0x29 0x26 0x00>;
			};

			spi@880000 {
				operating-points-v2 = <0x2f>;
				interconnect-names = "qup-core", "qup-config";
				clocks = <0x24 0x3a>;
				pinctrl-names = "default";
				pinctrl-0 = <0x2d 0x2e>;
				compatible = "qcom,geni-spi";
				reg = <0x00 0x880000 0x00 0x4000>;
				clock-names = "se";
				interrupts = <0x00 0x259 0x04>;
				status = "disabled";
				#address-cells = <0x01>;
				#size-cells = <0x00>;
				power-domains = <0x23 0x00>;
				interconnects = <0x2c 0x00 0x00 0x2c 0x02 0x00 0x28 0x00 0x00 0x29 0x26 0x00>;
			};

			serial@894000 {
				operating-points-v2 = <0x2f>;
				interconnect-names = "qup-core", "qup-config";
				clocks = <0x24 0x44>;
				pinctrl-names = "default";
				pinctrl-0 = <0x45>;
				compatible = "qcom,geni-uart";
				reg = <0x00 0x894000 0x00 0x4000>;
				clock-names = "se";
				interrupts = <0x00 0x25e 0x04>;
				status = "disabled";
				power-domains = <0x23 0x00>;
				interconnects = <0x2c 0x00 0x00 0x2c 0x02 0x00 0x28 0x00 0x00 0x29 0x26 0x00>;
			};

			spi@884000 {
				operating-points-v2 = <0x2f>;
				interconnect-names = "qup-core", "qup-config";
				clocks = <0x24 0x3c>;
				pinctrl-names = "default";
				pinctrl-0 = <0x32 0x33>;
				compatible = "qcom,geni-spi";
				reg = <0x00 0x884000 0x00 0x4000>;
				clock-names = "se";
				interrupts = <0x00 0x25a 0x04>;
				status = "disabled";
				#address-cells = <0x01>;
				#size-cells = <0x00>;
				power-domains = <0x23 0x00>;
				interconnects = <0x2c 0x00 0x00 0x2c 0x02 0x00 0x28 0x00 0x00 0x29 0x26 0x00>;
			};

			serial@880000 {
				operating-points-v2 = <0x2f>;
				interconnect-names = "qup-core", "qup-config";
				clocks = <0x24 0x3a>;
				pinctrl-names = "default";
				pinctrl-0 = <0x30>;
				compatible = "qcom,geni-uart";
				reg = <0x00 0x880000 0x00 0x4000>;
				clock-names = "se";
				interrupts = <0x00 0x259 0x04>;
				status = "disabled";
				power-domains = <0x23 0x00>;
				interconnects = <0x2c 0x00 0x00 0x2c 0x02 0x00 0x28 0x00 0x00 0x29 0x26 0x00>;
			};

			serial@88c000 {
				operating-points-v2 = <0x2f>;
				interconnect-names = "qup-core", "qup-config";
				clocks = <0x24 0x40>;
				pinctrl-names = "default";
				pinctrl-0 = <0x3a>;
				compatible = "qcom,geni-uart";
				reg = <0x00 0x88c000 0x00 0x4000>;
				clock-names = "se";
				interrupts = <0x00 0x25c 0x04>;
				status = "disabled";
				power-domains = <0x23 0x00>;
				interconnects = <0x2c 0x00 0x00 0x2c 0x02 0x00 0x28 0x00 0x00 0x29 0x26 0x00>;
			};

			i2c@890000 {
				interconnect-names = "qup-core", "qup-config", "qup-memory";
				clocks = <0x24 0x42>;
				required-opps = <0x13>;
				pinctrl-names = "default";
				pinctrl-0 = <0x3b>;
				compatible = "qcom,geni-i2c";
				reg = <0x00 0x890000 0x00 0x4000>;
				clock-names = "se";
				interrupts = <0x00 0x25d 0x04>;
				status = "okay";
				#address-cells = <0x01>;
				clock-frequency = <0x61a80>;
				#size-cells = <0x00>;
				power-domains = <0x23 0x00>;
				interconnects = <0x2c 0x00 0x00 0x2c 0x02 0x00 0x28 0x00 0x00 0x29 0x26 0x00 0x26 0x02 0x00 0x27 0x01 0x00>;

				keyboard@5 {
					interrupts-extended = <0x3c 0x21 0x08>;
					hid-descr-addr = <0x20>;
					pinctrl-names = "default";
					pinctrl-0 = <0x3d 0x3e>;
					compatible = "hid-over-i2c";
					reg = <0x05>;
				};

				touchpad@2c {
					interrupts-extended = <0x3c 0x5e 0x08>;
					hid-descr-addr = <0x20>;
					pinctrl-names = "default";
					pinctrl-0 = <0x3f 0x40>;
					compatible = "hid-over-i2c";
					reg = <0x2c>;
				};
			};

			i2c@884000 {
				interconnect-names = "qup-core", "qup-config", "qup-memory";
				clocks = <0x24 0x3c>;
				required-opps = <0x13>;
				pinctrl-names = "default";
				pinctrl-0 = <0x31>;
				compatible = "qcom,geni-i2c";
				reg = <0x00 0x884000 0x00 0x4000>;
				clock-names = "se";
				interrupts = <0x00 0x25a 0x04>;
				status = "disabled";
				#address-cells = <0x01>;
				#size-cells = <0x00>;
				power-domains = <0x23 0x00>;
				interconnects = <0x2c 0x00 0x00 0x2c 0x02 0x00 0x28 0x00 0x00 0x29 0x26 0x00 0x26 0x02 0x00 0x27 0x01 0x00>;
			};

			i2c@880000 {
				interconnect-names = "qup-core", "qup-config", "qup-memory";
				clocks = <0x24 0x3a>;
				required-opps = <0x13>;
				pinctrl-names = "default";
				pinctrl-0 = <0x2b>;
				compatible = "qcom,geni-i2c";
				reg = <0x00 0x880000 0x00 0x4000>;
				clock-names = "se";
				interrupts = <0x00 0x259 0x04>;
				status = "disabled";
				#address-cells = <0x01>;
				#size-cells = <0x00>;
				power-domains = <0x23 0x00>;
				interconnects = <0x2c 0x00 0x00 0x2c 0x02 0x00 0x28 0x00 0x00 0x29 0x26 0x00 0x26 0x02 0x00 0x27 0x01 0x00>;
			};
		};

		video-codec@aa00000 {
			operating-points-v2 = <0x9f>;
			iommus = <0x25 0xc00 0x60>;
			interconnect-names = "video-mem", "cpu-cfg";
			clocks = <0x9e 0x06 0x9e 0x03 0x9e 0x05 0x9e 0x02 0x9e 0x01>;
			compatible = "qcom,sc7180-venus";
			reg = <0x00 0xaa00000 0x00 0xff000>;
			clock-names = "core", "iface", "bus", "vcodec0_core", "vcodec0_bus";
			interrupts = <0x00 0xae 0x04>;
			memory-region = <0xbe>;
			status = "okay";
			power-domain-names = "venus", "vcodec0", "cx";
			power-domains = <0x9e 0x00 0x9e 0x01 0x23 0x00>;
			interconnects = <0xa0 0x06 0x00 0x27 0x01 0x00 0x28 0x00 0x00 0x29 0x31 0x00>;

			opp-table {
				phandle = <0x9f>;
				compatible = "operating-points-v2";

				opp-500000097 {
					opp-hz = <0x00 0x1dcd6561>;
					required-opps = <0xa2>;
				};

				opp-270000000 {
					opp-hz = <0x00 0x1017df80>;
					required-opps = <0x14>;
				};

				opp-340000000 {
					opp-hz = <0x00 0x1443fd00>;
					required-opps = <0xa1>;
				};

				opp-434000000 {
					opp-hz = <0x00 0x19de5080>;
					required-opps = <0x15>;
				};

				opp-150000000 {
					opp-hz = <0x00 0x8f0d180>;
					required-opps = <0x13>;
				};
			};
		};

		rxmacro@62600000 {
			clocks = <0xda 0x39 0x01 0xda 0x3a 0x01 0xda 0x66 0x01 0xda 0x67 0x01>;
			phandle = <0xdd>;
			#sound-dai-cells = <0x01>;
			compatible = "qcom,sm8250-lpass-rx-macro";
			reg = <0x00 0x62600000 0x00 0x1000>;
			clock-names = "mclk", "npl", "macro", "dcodec";
			status = "okay";
			#clock-cells = <0x00>;
			clock-output-names = "mclk";
		};

		rsc@18200000 {
			qcom,tcs-config = <0x02 0x02 0x00 0x03 0x01 0x03 0x03 0x01>;
			compatible = "qcom,sc7180-rpmh-apps-rsc", "qcom,rpmh-rsc";
			reg = <0x00 0x18200000 0x00 0x10000 0x00 0x18210000 0x00 0x10000 0x00 0x18220000 0x00 0x10000>;
			reg-names = "drv-0", "drv-1", "drv-2";
			interrupts = <0x00 0x03 0x04 0x00 0x04 0x04 0x00 0x05 0x04>;
			qcom,tcs-offset = <0xd00>;
			qcom,drv-id = <0x02>;

			power-controller {
				operating-points-v2 = <0xae>;
				phandle = <0x23>;
				#power-domain-cells = <0x01>;
				compatible = "qcom,sc7180-rpmhpd";

				opp-table {
					phandle = <0xae>;
					compatible = "operating-points-v2";

					opp1 {
						opp-level = <0x10>;
					};

					opp9 {
						opp-level = <0x150>;
					};

					opp5 {
						opp-level = <0xc0>;
						phandle = <0xa1>;
					};

					opp11 {
						opp-level = <0x1a0>;
					};

					opp2 {
						opp-level = <0x30>;
					};

					opp6 {
						opp-level = <0xe0>;
					};

					opp3 {
						opp-level = <0x40>;
						phandle = <0x13>;
					};

					opp8 {
						opp-level = <0x140>;
					};

					opp4 {
						opp-level = <0x80>;
						phandle = <0x14>;
					};

					opp10 {
						opp-level = <0x180>;
						phandle = <0xa2>;
					};

					opp7 {
						opp-level = <0x100>;
						phandle = <0x15>;
					};
				};
			};

			regulators-0 {
				qcom,pmic-id = "a";
				compatible = "qcom,pm6150-rpmh-regulators";

				ldo4 {
					regulator-min-microvolt = <0xd6d80>;
					phandle = <0x94>;
					regulator-max-microvolt = <0xd6d80>;
					regulator-initial-mode = <0x03>;
				};

				ldo9 {
					regulator-min-microvolt = <0xa21c0>;
					phandle = <0xb0>;
					regulator-max-microvolt = <0xa21c0>;
					regulator-initial-mode = <0x03>;
				};

				ldo11 {
					regulator-min-microvolt = <0x1b7740>;
					phandle = <0x95>;
					regulator-max-microvolt = <0x1b7740>;
					regulator-initial-mode = <0x03>;
				};

				ldo17 {
					regulator-min-microvolt = <0x2f1e80>;
					phandle = <0x96>;
					regulator-max-microvolt = <0x2f1e80>;
					regulator-initial-mode = <0x03>;
				};

				ldo19 {
					regulator-min-microvolt = <0x2d2a80>;
					phandle = <0xba>;
					regulator-max-microvolt = <0x2d2a80>;
					regulator-initial-mode = <0x03>;
				};

				ldo12 {
					regulator-min-microvolt = <0x1b7740>;
					phandle = <0xb9>;
					regulator-max-microvolt = <0x1b7740>;
					regulator-initial-mode = <0x03>;
				};
			};

			regulators-1 {
				qcom,pmic-id = "c";
				compatible = "qcom,pm6150l-rpmh-regulators";

				ldo1 {
					regulator-min-microvolt = <0x1b7740>;
					phandle = <0xb1>;
					regulator-max-microvolt = <0x1b7740>;
					regulator-initial-mode = <0x03>;
				};

				ldo2 {
					regulator-min-microvolt = <0x13e5c0>;
					phandle = <0xb2>;
					regulator-max-microvolt = <0x13e5c0>;
					regulator-initial-mode = <0x03>;
				};

				ldo3 {
					regulator-min-microvolt = <0x124f80>;
					phandle = <0x97>;
					regulator-max-microvolt = <0x124f80>;
					regulator-initial-mode = <0x03>;
				};

				ldo11 {
					phandle = <0xb4>;
					regulator-initial-mode = <0x03>;
				};

				ldo10 {
					regulator-min-microvolt = <0x326a40>;
					phandle = <0xb3>;
					regulator-max-microvolt = <0x326a40>;
					regulator-initial-mode = <0x03>;
				};
			};

			clock-controller {
				clocks = <0xad>;
				phandle = <0x21>;
				compatible = "qcom,sc7180-rpmh-clk";
				clock-names = "xo";
				#clock-cells = <0x01>;
			};

			bcm-voter {
				phandle = <0x5b>;
				compatible = "qcom,bcm-voter";
			};
		};

		remoteproc@4080000 {
			interrupt-names = "wdog", "fatal", "ready", "handover", "stop-ack", "shutdown-ack";
			interrupts-extended = <0x01 0x00 0x10a 0x01 0x64 0x00 0x01 0x64 0x01 0x01 0x64 0x02 0x01 0x64 0x03 0x01 0x64 0x07 0x01>;
			clocks = <0x21 0x00>;
			qcom,qmp = <0x61>;
			compatible = "qcom,sc7180-mpss-pas";
			reg = <0x00 0x4080000 0x00 0x4040>;
			clock-names = "xo";
			memory-region = <0x65>;
			status = "okay";
			power-domain-names = "cx", "mx", "mss";
			power-domains = <0x23 0x00 0x23 0x03 0x23 0x07>;
			qcom,smem-states = <0x66 0x00>;
			firmware-name = "qcom/sc7180/tcl/qcmpss7180_nm.mbn";
			qcom,smem-state-names = "stop";

			glink-edge {
				qcom,remote-pid = <0x01>;
				mboxes = <0x20 0x0c>;
				interrupts = <0x00 0x1c1 0x01>;
				label = "modem";
			};
		};

		funnel@6041000 {
			clocks = <0x61>;
			compatible = "arm,coresight-dynamic-funnel", "arm,primecell";
			reg = <0x00 0x6041000 0x00 0x1000>;
			clock-names = "apb_pclk";
			status = "disabled";

			out-ports {

				port {

					endpoint {
						phandle = <0x73>;
						remote-endpoint = <0x6e>;
					};
				};
			};

			in-ports {
				#address-cells = <0x01>;
				#size-cells = <0x00>;

				port@7 {
					reg = <0x07>;

					endpoint {
						phandle = <0x6d>;
						remote-endpoint = <0x6f>;
					};
				};
			};
		};

		gpu@5000000 {
			operating-points-v2 = <0x68>;
			iommus = <0x67 0x00>;
			nvmem-cell-names = "speed_bin";
			interconnect-names = "gfx-mem";
			qcom,gmu = <0x69>;
			phandle = <0xd7>;
			compatible = "qcom,adreno-618.0", "qcom,adreno";
			nvmem-cells = <0x6a>;
			reg = <0x00 0x5000000 0x00 0x40000 0x00 0x509e000 0x00 0x1000 0x00 0x5061000 0x00 0x800>;
			reg-names = "kgsl_3d0_reg_memory", "cx_mem", "cx_dbgc";
			interrupts = <0x00 0x12c 0x04>;
			status = "okay";
			interconnects = <0x28 0x08 0x00 0x27 0x01 0x00>;
			#cooling-cells = <0x02>;

			opp-table {
				phandle = <0x68>;
				compatible = "operating-points-v2";

				opp-825000000 {
					opp-hz = <0x00 0x312c8040>;
					opp-level = <0x1a0>;
					opp-supported-hw = <0x04>;
					opp-peak-kBps = <0x823020>;
				};

				opp-650000000 {
					opp-hz = <0x00 0x26be3680>;
					opp-level = <0x140>;
					opp-supported-hw = <0x07>;
					opp-peak-kBps = <0x6e1b80>;
				};

				opp-355000000 {
					opp-hz = <0x00 0x1528dec0>;
					opp-level = <0x80>;
					opp-supported-hw = <0x07>;
					opp-peak-kBps = <0x2ee000>;
				};

				opp-267000000 {
					opp-hz = <0x00 0xfea18c0>;
					opp-level = <0x40>;
					opp-supported-hw = <0x07>;
					opp-peak-kBps = <0x2ee000>;
				};

				opp-800000000 {
					opp-hz = <0x00 0x2faf0800>;
					opp-level = <0x180>;
					opp-supported-hw = <0x07>;
					opp-peak-kBps = <0x823020>;
				};

				opp-565000000 {
					opp-hz = <0x00 0x21ad3740>;
					opp-level = <0x100>;
					opp-supported-hw = <0x07>;
					opp-peak-kBps = <0x5294a0>;
				};

				opp-430000000 {
					opp-hz = <0x00 0x19a14780>;
					opp-level = <0xc0>;
					opp-supported-hw = <0x07>;
					opp-peak-kBps = <0x5294a0>;
				};

				opp-180000000 {
					opp-hz = <0x00 0xaba9500>;
					opp-level = <0x30>;
					opp-supported-hw = <0x07>;
					opp-peak-kBps = <0x1b86e0>;
				};
			};

			zap-shader {
				memory-region = <0xbd>;
				firmware-name = "qcom/sc7180/tcl/qcdxkmsuc7180.mbn";
			};
		};

		clock-controller@100000 {
			clocks = <0x21 0x00 0x21 0x01 0x22>;
			phandle = <0x24>;
			#power-domain-cells = <0x01>;
			compatible = "qcom,gcc-sc7180";
			reg = <0x00 0x100000 0x00 0x1f0000>;
			clock-names = "bi_tcxo", "bi_tcxo_ao", "sleep_clk";
			#clock-cells = <0x01>;
			power-domains = <0x23 0x00>;
			#reset-cells = <0x01>;
		};

		codec@62770000 {
			clocks = <0xdb 0x00 0xda 0x66 0x01 0xda 0x67 0x01>;
			#sound-dai-cells = <0x01>;
			compatible = "qcom,sm7180-lpass-va-macro", "qcom,sm8250-lpass-va-macro";
			reg = <0x00 0x62770000 0x00 0x1000>;
			clock-names = "mclk", "macro", "dcodec";
			status = "okay";
			#clock-cells = <0x00>;
			clock-frequency = <0x927c00>;
			clock-output-names = "fsgen";
		};

		iommu@5040000 {
			clocks = <0x24 0x26 0x24 0x23>;
			phandle = <0x67>;
			#global-interrupts = <0x02>;
			#iommu-cells = <0x01>;
			compatible = "qcom,sc7180-smmu-v2", "qcom,adreno-smmu", "qcom,smmu-v2";
			reg = <0x00 0x5040000 0x00 0x10000>;
			clock-names = "bus", "iface";
			interrupts = <0x00 0xe5 0x04 0x00 0xe7 0x04 0x00 0x16c 0x01 0x00 0x16d 0x01 0x00 0x16e 0x01 0x00 0x16f 0x01 0x00 0x170 0x01 0x00 0x171 0x01 0x00 0x172 0x01 0x00 0x173 0x01>;
			status = "okay";
			power-domains = <0x6b 0x00>;
		};

		stm@6002000 {
			clocks = <0x61>;
			compatible = "arm,coresight-stm", "arm,primecell";
			reg = <0x00 0x6002000 0x00 0x1000 0x00 0x16280000 0x00 0x180000>;
			clock-names = "apb_pclk";
			reg-names = "stm-base", "stm-stimulus-base";
			status = "disabled";

			out-ports {

				port {

					endpoint {
						phandle = <0x6f>;
						remote-endpoint = <0x6d>;
					};
				};
			};
		};

		thermal-sensor@c265000 {
			interrupt-names = "uplow", "critical";
			#thermal-sensor-cells = <0x01>;
			phandle = <0xd9>;
			compatible = "qcom,sc7180-tsens", "qcom,tsens-v2";
			reg = <0x00 0xc265000 0x00 0x1ff 0x00 0xc223000 0x00 0x1ff>;
			interrupts = <0x00 0x1fb 0x04 0x00 0x1fd 0x04>;
			#qcom,sensors = <0x0a>;
			status = "okay";
		};

		interconnect@170e000 {
			compatible = "qcom,sc7180-compute-noc";
			reg = <0x00 0x170e000 0x00 0x6000>;
			#interconnect-cells = <0x02>;
			status = "disabled";
			qcom,bcm-voters = <0x5b>;
		};

		clock-controller@62780000 {
			clocks = <0xda 0x66 0x01 0xda 0x67 0x01 0xda 0x3a 0x01>;
			phandle = <0xdb>;
			compatible = "qcom,sm7180-lpass-aoncc", "qcom,sm8250-lpass-aoncc";
			reg = <0x00 0x62780000 0x00 0x40000>;
			clock-names = "core", "audio", "bus";
			status = "okay";
			#clock-cells = <0x01>;
		};

		efuse@784000 {
			clocks = <0x24 0x82>;
			compatible = "qcom,sc7180-qfprom", "qcom,qfprom";
			reg = <0x00 0x784000 0x00 0x7a0 0x00 0x780000 0x00 0x7a0 0x00 0x782000 0x00 0x100 0x00 0x786000 0x00 0x1fff>;
			clock-names = "core";
			#address-cells = <0x01>;
			#size-cells = <0x01>;

			gpu-speed-bin@1d2 {
				phandle = <0x6a>;
				reg = <0x1d2 0x02>;
				bits = <0x05 0x08>;
			};

			hstx-trim-primary@25b {
				phandle = <0x93>;
				reg = <0x25b 0x01>;
				bits = <0x01 0x03>;
			};
		};

		gmu@506a000 {
			interrupt-names = "hfi", "gmu";
			operating-points-v2 = <0x6c>;
			iommus = <0x67 0x05>;
			clocks = <0x6b 0x03 0x6b 0x06 0x24 0x16 0x24 0x26>;
			phandle = <0x69>;
			compatible = "qcom,adreno-gmu-618.0", "qcom,adreno-gmu";
			reg = <0x00 0x506a000 0x00 0x31000 0x00 0xb290000 0x00 0x10000 0x00 0xb490000 0x00 0x10000>;
			clock-names = "gmu", "cxo", "axi", "memnoc";
			reg-names = "gmu", "gmu_pdc", "gmu_pdc_seq";
			interrupts = <0x00 0x130 0x04 0x00 0x131 0x04>;
			status = "okay";
			power-domain-names = "cx", "gx";
			power-domains = <0x6b 0x00 0x6b 0x01>;

			opp-table {
				phandle = <0x6c>;
				compatible = "operating-points-v2";

				opp-200000000 {
					opp-hz = <0x00 0xbebc200>;
					opp-level = <0x30>;
				};
			};
		};

		wifi@18800000 {
			iommus = <0x25 0xc0 0x01>;
			vdd-3.3-ch0-supply = <0xb3>;
			qcom,msa-fixed-perm;
			vdd-0.8-cx-mx-supply = <0xb0>;
			vdd-1.8-xo-supply = <0xb1>;
			compatible = "qcom,wcn3990-wifi";
			reg = <0x00 0x18800000 0x00 0x800000>;
			reg-names = "membase";
			interrupts = <0x00 0x19e 0x04 0x00 0x19f 0x04 0x00 0x1a0 0x04 0x00 0x1a1 0x04 0x00 0x1a2 0x04 0x00 0x1a3 0x04 0x00 0x1a4 0x04 0x00 0x1a5 0x04 0x00 0x1a6 0x04 0x00 0x1a7 0x04 0x00 0x1a8 0x04 0x00 0x1a9 0x04>;
			memory-region = <0xaf>;
			status = "okay";
			vdd-3.3-ch1-supply = <0xb4>;
			vdd-1.3-rfa-supply = <0xb2>;
		};

		dma@10a2000 {
			compatible = "qcom,sc7180-dcc", "qcom,dcc";
			reg = <0x00 0x10a2000 0x00 0x1000 0x00 0x10ae000 0x00 0x2000>;
			status = "disabled";
		};

		timer@17c20000 {
			compatible = "arm,armv7-timer-mem";
			reg = <0x00 0x17c20000 0x00 0x1000>;
			status = "disabled";
			#address-cells = <0x01>;
			#size-cells = <0x01>;
			ranges = <0x00 0x00 0x00 0x20000000>;

			frame@17c29000 {
				reg = <0x17c29000 0x1000>;
				frame-number = <0x04>;
				interrupts = <0x00 0x0c 0x04>;
				status = "disabled";
			};

			frame@17c23000 {
				reg = <0x17c23000 0x1000>;
				frame-number = <0x01>;
				interrupts = <0x00 0x09 0x04>;
				status = "disabled";
			};

			frame@17c21000 {
				reg = <0x17c21000 0x1000 0x17c22000 0x1000>;
				frame-number = <0x00>;
				interrupts = <0x00 0x08 0x04 0x00 0x06 0x04>;
			};

			frame@17c25000 {
				reg = <0x17c25000 0x1000>;
				frame-number = <0x02>;
				interrupts = <0x00 0x0a 0x04>;
				status = "disabled";
			};

			frame@17c2b000 {
				reg = <0x17c2b000 0x1000>;
				frame-number = <0x05>;
				interrupts = <0x00 0x0d 0x04>;
				status = "disabled";
			};

			frame@17c27000 {
				reg = <0x17c27000 0x1000>;
				frame-number = <0x03>;
				interrupts = <0x00 0x0b 0x04>;
				status = "disabled";
			};

			frame@17c2d000 {
				reg = <0x17c2d000 0x1000>;
				frame-number = <0x06>;
				interrupts = <0x00 0x0e 0x04>;
				status = "disabled";
			};
		};

		spmi@c440000 {
			interrupt-names = "periph_irq";
			interrupts-extended = <0x63 0x01 0x04>;
			interrupt-controller;
			compatible = "qcom,spmi-pmic-arb";
			reg = <0x00 0xc440000 0x00 0x1100 0x00 0xc600000 0x00 0x2000000 0x00 0xe600000 0x00 0x100000 0x00 0xe700000 0x00 0xa0000 0x00 0xc40a000 0x00 0x26000>;
			#interrupt-cells = <0x04>;
			reg-names = "core", "chnls", "obsrvr", "intr", "cnfg";
			status = "disabled";
			qcom,channel = <0x00>;
			#address-cells = <0x02>;
			qcom,ee = <0x00>;
			#size-cells = <0x00>;
		};

		syscon@1f60000 {
			compatible = "qcom,sc7180-tcsr", "syscon";
			reg = <0x00 0x1f60000 0x00 0x20000>;
		};

		pinctrl@3500000 {
			gpio-ranges = <0x3c 0x00 0x00 0x78>;
			#gpio-cells = <0x02>;
			gpio-controller;
			wakeup-parent = <0x63>;
			gpio-reserved-ranges = <0x3a 0x05>;
			interrupt-controller;
			phandle = <0x3c>;
			compatible = "qcom,sc7180-pinctrl";
			reg = <0x00 0x3500000 0x00 0x300000 0x00 0x3900000 0x00 0x300000 0x00 0x3d00000 0x00 0x300000>;
			#interrupt-cells = <0x02>;
			reg-names = "west", "north", "south";
			interrupts = <0x00 0xd0 0x04>;

			qup-uart0-default-state {
				phandle = <0x30>;

				rts-pins {
					function = "qup00";
					pins = "gpio35";
				};

				cts-pins {
					function = "qup00";
					pins = "gpio34";
				};

				tx-pins {
					function = "qup00";
					pins = "gpio36";
				};

				rx-pins {
					function = "qup00";
					pins = "gpio37";
				};
			};

			qup-spi1-cs-gpio-state {
				function = "gpio";
				pins = "gpio3";
			};

			qup-i2c9-default-state {
				phandle = <0x51>;
				function = "qup13_i2c";
				pins = "gpio46", "gpio47";
			};

			qup-i2c7-default-state {
				phandle = <0x4b>;
				function = "qup11_i2c";
				pins = "gpio6", "gpio7";
			};

			qup-spi11-cs-gpio-state {
				function = "gpio";
				pins = "gpio56";
			};

			qup-i2c6-default-state {
				phandle = <0x46>;
				function = "qup10";
				pins = "gpio59", "gpio60";
			};

			qup-i2c4-default-state {
				phandle = <0x3b>;
				drive-strength = <0x02>;
				function = "qup04_i2c";
				pins = "gpio115", "gpio116";
				bias-disable;
			};

			qup-spi5-spi-state {
				phandle = <0x43>;
				function = "qup05";
				pins = "gpio25", "gpio26", "gpio27";
			};

			qup-spi3-spi-state {
				phandle = <0x38>;
				function = "qup03";
				pins = "gpio38", "gpio39", "gpio40";
			};

			qspi-cs1-state {
				function = "qspi_cs";
				pins = "gpio72";
			};

			qup-uart3-default-state {
				phandle = <0x3a>;

				rts-pins {
					function = "qup03";
					pins = "gpio39";
				};

				cts-pins {
					function = "qup03";
					pins = "gpio38";
				};

				tx-pins {
					function = "qup03";
					pins = "gpio40";
				};

				rx-pins {
					function = "qup03";
					pins = "gpio41";
				};
			};

			qup-spi0-cs-state {
				phandle = <0x2e>;
				function = "qup00";
				pins = "gpio37";
			};

			qup-uart8-default-state {
				phandle = <0x50>;

				tx-pins {
					function = "qup12";
					pins = "gpio44";
				};

				rx-pins {
					function = "qup12";
					pins = "gpio45";
				};
			};

			qup-i2c8-default-state {
				phandle = <0x4d>;
				function = "qup12";
				pins = "gpio42", "gpio43";
			};

			qup-spi6-cs-state {
				phandle = <0x49>;
				function = "qup10";
				pins = "gpio62";
			};

			qup-i2c2-default-state {
				phandle = <0x35>;
				drive-strength = <0x02>;
				function = "qup02_i2c";
				pins = "gpio15", "gpio16";
				bias-disable;
			};

			qup-uart9-default-state {
				phandle = <0x52>;

				tx-pins {
					function = "qup13_uart";
					pins = "gpio46";
				};

				rx-pins {
					function = "qup13_uart";
					pins = "gpio47";
				};
			};

			qup-spi3-cs-state {
				phandle = <0x39>;
				function = "qup03";
				pins = "gpio41";
			};

			qup-spi1-spi-state {
				phandle = <0x32>;
				function = "qup01";
				pins = "gpio0", "gpio1", "gpio2";
			};

			pri-mi2s-mclk-active-state {
				function = "lpass_ext";
				pins = "gpio57";
			};

			qup-spi8-cs-state {
				phandle = <0x4f>;
				function = "qup12";
				pins = "gpio45";
			};

			keyboard-enable-state {
				phandle = <0x3e>;
				output-high;
				drive-strength = <0x02>;
				function = "gpio";
				pins = "gpio32";
				bias-disable;
			};

			qup-spi6-cs-gpio-state {
				function = "gpio";
				pins = "gpio62";
			};

			touchpad-irq-state {
				phandle = <0x3f>;
				drive-strength = <0x02>;
				function = "gpio";
				pins = "gpio94";
				bias-disable;
			};

			qup-i2c0-default-state {
				phandle = <0x2b>;
				function = "qup00";
				pins = "gpio34", "gpio35";
			};

			qup-spi6-spi-state {
				phandle = <0x48>;
				function = "qup10";
				pins = "gpio59", "gpio60", "gpio61";
			};

			qup-uart7-default-state {
				phandle = <0x4c>;

				tx-pins {
					function = "qup11_uart";
					pins = "gpio6";
				};

				rx-pins {
					function = "qup11_uart";
					pins = "gpio7";
				};
			};

			qspi-data1-state {
				function = "qspi_data";
				pins = "gpio65";
			};

			touchpad-enable-state {
				phandle = <0x40>;
				output-high;
				drive-strength = <0x02>;
				function = "gpio";
				pins = "gpio25";
				bias-disable;
			};

			qup-uart11-default-state {
				phandle = <0x5a>;

				rts-pins {
					function = "qup15";
					pins = "gpio54";
				};

				cts-pins {
					function = "qup15";
					pins = "gpio53";
				};

				tx-pins {
					function = "qup15";
					pins = "gpio55";
				};

				rx-pins {
					function = "qup15";
					pins = "gpio56";
				};
			};

			qup-spi10-cs-gpio-state {
				function = "gpio";
				pins = "gpio89";
			};

			qup-i2c10-default-state {
				phandle = <0x53>;
				function = "qup14";
				pins = "gpio86", "gpio87";
			};

			ter-mi2s-active-state {
				function = "mi2s_2";
				pins = "gpio63", "gpio64", "gpio65", "gpio66";
			};

			keyboard-irq-state {
				phandle = <0x3d>;
				drive-strength = <0x02>;
				function = "gpio";
				pins = "gpio33";
				bias-pull-up;
			};

			sec-mi2s-active-state {
				function = "mi2s_1";
				pins = "gpio49", "gpio50", "gpio51";
			};

			qup-i2c1-default-state {
				phandle = <0x31>;
				function = "qup01";
				pins = "gpio0", "gpio1";
			};

			qup-spi8-spi-state {
				phandle = <0x4e>;
				function = "qup12";
				pins = "gpio42", "gpio43", "gpio44";
			};

			qspi-data23-state {
				function = "qspi_data";
				pins = "gpio66", "gpio67";
			};

			pri-mi2s-active-state {
				function = "mi2s_0";
				pins = "gpio53", "gpio54", "gpio55", "gpio56";
			};

			qspi-cs0-state {
				function = "qspi_cs";
				pins = "gpio68";
			};

			qup-uart6-default-state {
				phandle = <0x4a>;

				rts-pins {
					function = "qup10";
					pins = "gpio60";
				};

				cts-pins {
					function = "qup10";
					pins = "gpio59";
				};

				tx-pins {
					function = "qup10";
					pins = "gpio61";
				};

				rx-pins {
					function = "qup10";
					pins = "gpio62";
				};
			};

			qup-i2c5-default-state {
				phandle = <0x42>;
				function = "qup05";
				pins = "gpio25", "gpio26";
			};

			qup-spi1-cs-state {
				phandle = <0x33>;
				function = "qup01";
				pins = "gpio3";
			};

			qup-uart2-default-state {
				phandle = <0x36>;

				tx-pins {
					function = "qup02_uart";
					pins = "gpio15";
				};

				rx-pins {
					function = "qup02_uart";
					pins = "gpio16";
				};
			};

			qup-spi0-cs-gpio-state {
				function = "gpio";
				pins = "gpio37";
			};

			qup-spi11-spi-state {
				phandle = <0x58>;
				function = "qup15";
				pins = "gpio53", "gpio54", "gpio55";
			};

			qup-spi11-cs-state {
				phandle = <0x59>;
				function = "qup15";
				pins = "gpio56";
			};

			qup-uart4-default-state {
				phandle = <0x41>;

				tx-pins {
					function = "qup04_uart";
					pins = "gpio115";
				};

				rx-pins {
					function = "qup04_uart";
					pins = "gpio116";
				};
			};

			qup-spi10-spi-state {
				phandle = <0x54>;
				function = "qup14";
				pins = "gpio86", "gpio87", "gpio88";
			};

			qup-uart5-default-state {
				phandle = <0x45>;

				rts-pins {
					function = "qup05";
					pins = "gpio26";
				};

				cts-pins {
					function = "qup05";
					pins = "gpio25";
				};

				tx-pins {
					function = "qup05";
					pins = "gpio27";
				};

				rx-pins {
					function = "qup05";
					pins = "gpio28";
				};
			};

			qup-spi8-cs-gpio-state {
				function = "gpio";
				pins = "gpio45";
			};

			qup-i2c11-default-state {
				phandle = <0x57>;
				function = "qup15";
				pins = "gpio53", "gpio54";
			};

			qspi-clk-state {
				function = "qspi_clk";
				pins = "gpio63";
			};

			qup-spi5-cs-gpio-state {
				function = "gpio";
				pins = "gpio28";
			};

			qup-spi3-cs-gpio-state {
				function = "gpio";
				pins = "gpio41";
			};

			qup-spi10-cs-state {
				phandle = <0x55>;
				function = "qup14";
				pins = "gpio89";
			};

			qup-spi5-cs-state {
				phandle = <0x44>;
				function = "qup05";
				pins = "gpio28";
			};

			qup-uart10-default-state {
				phandle = <0x56>;

				rts-pins {
					function = "qup14";
					pins = "gpio87";
				};

				cts-pins {
					function = "qup14";
					pins = "gpio86";
				};

				tx-pins {
					function = "qup14";
					pins = "gpio88";
				};

				rx-pins {
					function = "qup14";
					pins = "gpio89";
				};
			};

			dp-hot-plug-det-state {
				function = "dp_hot";
				pins = "gpio117";
			};

			qup-i2c3-default-state {
				phandle = <0x37>;
				function = "qup03";
				pins = "gpio38", "gpio39";
			};

			qspi-data0-state {
				function = "qspi_data";
				pins = "gpio64";
			};

			qup-uart1-default-state {
				phandle = <0x34>;

				rts-pins {
					function = "qup01";
					pins = "gpio1";
				};

				cts-pins {
					function = "qup01";
					pins = "gpio0";
				};

				tx-pins {
					function = "qup01";
					pins = "gpio2";
				};

				rx-pins {
					function = "qup01";
					pins = "gpio3";
				};
			};

			qup-spi0-spi-state {
				phandle = <0x2d>;
				function = "qup00";
				pins = "gpio34", "gpio35", "gpio36";
			};
		};

		interconnect@1500000 {
			phandle = <0x29>;
			compatible = "qcom,sc7180-config-noc";
			reg = <0x00 0x1500000 0x00 0x28000>;
			#interconnect-cells = <0x02>;
			qcom,bcm-voters = <0x5b>;
		};

		interconnect@9160000 {
			compatible = "qcom,sc7180-dc-noc";
			reg = <0x00 0x9160000 0x00 0x3200>;
			#interconnect-cells = <0x02>;
			qcom,bcm-voters = <0x5b>;
		};

		ipa@1e40000 {
			interrupt-names = "ipa", "gsi", "ipa-clock-query", "ipa-setup-ready";
			iommus = <0x25 0x440 0x00 0x25 0x442 0x00>;
			interconnect-names = "memory", "imem", "config";
			interrupts-extended = <0x01 0x00 0x137 0x01 0x01 0x00 0x1b0 0x04 0x5f 0x00 0x01 0x5f 0x01 0x01>;
			clocks = <0x21 0x0c>;
			qcom,qmp = <0x61>;
			compatible = "qcom,sc7180-ipa";
			reg = <0x00 0x1e40000 0x00 0x7000 0x00 0x1e47000 0x00 0x2000 0x00 0x1e04000 0x00 0x2c000>;
			clock-names = "core";
			reg-names = "ipa-reg", "ipa-shared", "gsi";
			status = "disabled";
			interconnects = <0x47 0x05 0x00 0x27 0x01 0x00 0x47 0x05 0x00 0x60 0x09 0x00 0x28 0x00 0x00 0x29 0x19 0x00>;
			qcom,smem-states = <0x62 0x00 0x62 0x01>;
			qcom,smem-state-names = "ipa-clock-enabled-valid", "ipa-clock-enabled";
		};

		remoteproc@62400000 {
			interrupt-names = "wdog", "fatal", "ready", "handover", "stop-ack";
			interrupts-extended = <0x01 0x00 0xa2 0x01 0xb5 0x00 0x01 0xb5 0x01 0x01 0xb5 0x02 0x01 0xb5 0x03 0x01>;
			clocks = <0x21 0x00>;
			qcom,qmp = <0x61>;
			compatible = "qcom,sc7180-adsp-pas";
			reg = <0x00 0x62400000 0x00 0x100>;
			clock-names = "xo";
			memory-region = <0xc0>;
			status = "okay";
			power-domain-names = "lcx", "lmx";
			power-domains = <0x23 0x06 0x23 0x05>;
			qcom,smem-states = <0xb6 0x00>;
			firmware-name = "qcom/sc7180/tcl/b220g/qcadsp7180.mbn";
			qcom,smem-state-names = "stop";

			glink-edge {
				qcom,remote-pid = <0x02>;
				mboxes = <0x20 0x08>;
				interrupts = <0x00 0x9c 0x01>;
				label = "lpass";

				fastrpc {
					qcom,glink-channels = "fastrpcglink-apps-dsp";
					compatible = "qcom,fastrpc";
					#address-cells = <0x01>;
					label = "adsp";
					#size-cells = <0x00>;

					compute-cb@3 {
						iommus = <0x25 0x1003 0x00>;
						compatible = "qcom,fastrpc-compute-cb";
						reg = <0x03>;
					};

					compute-cb@4 {
						iommus = <0x25 0x1004 0x00>;
						compatible = "qcom,fastrpc-compute-cb";
						reg = <0x04>;
					};

					compute-cb@5 {
						iommus = <0x25 0x1005 0x00>;
						qcom,nsessions = <0x05>;
						compatible = "qcom,fastrpc-compute-cb";
						reg = <0x05>;
					};
				};

				apr {
					qcom,domain = <0x04>;
					qcom,glink-channels = "apr_audio_svc";
					compatible = "qcom,apr-v2";
					#address-cells = <0x01>;
					#size-cells = <0x00>;

					service@8 {
						qcom,protection-domain = "avs/audio", "msm/adsp/audio_pd";
						compatible = "qcom,q6adm";
						reg = <0x08>;

						routing {
							#sound-dai-cells = <0x00>;
							compatible = "qcom,q6adm-routing";
						};
					};

					service@7 {
						qcom,protection-domain = "avs/audio", "msm/adsp/audio_pd";
						compatible = "qcom,q6asm";
						reg = <0x07>;

						dais {
							iommus = <0x25 0x1001 0x00>;
							#sound-dai-cells = <0x01>;
							compatible = "qcom,q6asm-dais";
							#address-cells = <0x01>;
							#size-cells = <0x00>;

							dai@0 {
								reg = <0x00>;
							};
						};
					};

					service@4 {
						qcom,protection-domain = "avs/audio", "msm/adsp/audio_pd";
						compatible = "qcom,q6afe";
						reg = <0x04>;

						dais {
							#sound-dai-cells = <0x01>;
							compatible = "qcom,q6afe-dais";
							#address-cells = <0x01>;
							#size-cells = <0x00>;
						};

						clock-controller {
							phandle = <0xda>;
							compatible = "qcom,q6afe-clocks";
							#clock-cells = <0x02>;
						};
					};

					service@3 {
						qcom,protection-domain = "avs/audio", "msm/adsp/audio_pd";
						compatible = "qcom,q6core";
						reg = <0x03>;
					};
				};
			};
		};

		crypto@1d90000 {
			clocks = <0x24 0x65>;
			phandle = <0x5d>;
			compatible = "qcom,sc7180-inline-crypto-engine", "qcom,inline-crypto-engine";
			reg = <0x00 0x1d90000 0x00 0x8000>;
			status = "okay";
		};

		mmc@8804000 {
			interrupt-names = "hc_irq", "pwr_irq";
			operating-points-v2 = <0x91>;
			iommus = <0x25 0x80 0x00>;
			interconnect-names = "sdhc-ddr", "cpu-sdhc";
			clocks = <0x24 0x5d 0x24 0x5e 0x21 0x00>;
			bus-width = <0x04>;
			compatible = "qcom,sc7180-sdhci", "qcom,sdhci-msm-v5";
			reg = <0x00 0x8804000 0x00 0x1000>;
			clock-names = "iface", "core", "xo";
			interrupts = <0x00 0xcc 0x04 0x00 0xde 0x04>;
			status = "disabled";
			power-domains = <0x23 0x00>;
			interconnects = <0x26 0x03 0x00 0x27 0x01 0x00 0x28 0x00 0x00 0x29 0x28 0x00>;

			opp-table {
				phandle = <0x91>;
				compatible = "operating-points-v2";

				opp-202000000 {
					opp-hz = <0x00 0xc0a4680>;
					required-opps = <0x15>;
					opp-avg-kBps = <0x30d40 0x00>;
					opp-peak-kBps = <0x5265c0 0x186a00>;
				};

				opp-100000000 {
					opp-hz = <0x00 0x5f5e100>;
					required-opps = <0x13>;
					opp-avg-kBps = <0x186a0 0x00>;
					opp-peak-kBps = <0x1b7740 0x927c0>;
				};
			};
		};

		interconnect@1638000 {
			phandle = <0x27>;
			compatible = "qcom,sc7180-mc-virt";
			reg = <0x00 0x1638000 0x00 0x1000>;
			#interconnect-cells = <0x02>;
			qcom,bcm-voters = <0x5b>;
		};

		reset-controller@c2a0000 {
			compatible = "qcom,sc7180-aoss-cc", "qcom,sdm845-aoss-cc";
			reg = <0x00 0xc2a0000 0x00 0x31000>;
			#reset-cells = <0x01>;
		};

		thermal-sensor@c263000 {
			interrupt-names = "uplow", "critical";
			#thermal-sensor-cells = <0x01>;
			phandle = <0xc1>;
			compatible = "qcom,sc7180-tsens", "qcom,tsens-v2";
			reg = <0x00 0xc263000 0x00 0x1ff 0x00 0xc222000 0x00 0x1ff>;
			interrupts = <0x00 0x1fa 0x04 0x00 0x1fc 0x04>;
			#qcom,sensors = <0x0f>;
			status = "okay";
		};

		interconnect@1740000 {
			phandle = <0xa0>;
			compatible = "qcom,sc7180-mmss-noc";
			reg = <0x00 0x1740000 0x00 0x1c100>;
			#interconnect-cells = <0x02>;
			status = "okay";
			qcom,bcm-voters = <0x5b>;
		};

		etm@7340000 {
			arm,coresight-loses-context-with-cpu;
			clocks = <0x61>;
			qcom,skip-power-up;
			cpu = <0x0e>;
			compatible = "arm,coresight-etm4x", "arm,primecell";
			reg = <0x00 0x7340000 0x00 0x1000>;
			clock-names = "apb_pclk";
			status = "disabled";

			out-ports {

				port {

					endpoint {
						phandle = <0x8a>;
						remote-endpoint = <0x81>;
					};
				};
			};
		};

		power-management@c300000 {
			mboxes = <0x20 0x00>;
			phandle = <0x61>;
			compatible = "qcom,sc7180-aoss-qmp", "qcom,aoss-qmp";
			reg = <0x00 0xc300000 0x00 0x400>;
			interrupts = <0x00 0x185 0x01>;
			#clock-cells = <0x00>;
		};

		interconnect@16e0000 {
			phandle = <0x26>;
			compatible = "qcom,sc7180-aggre1-noc";
			reg = <0x00 0x16e0000 0x00 0x15080>;
			#interconnect-cells = <0x02>;
			qcom,bcm-voters = <0x5b>;
		};

		interconnect@9680000 {
			phandle = <0x28>;
			compatible = "qcom,sc7180-gem-noc";
			reg = <0x00 0x9680000 0x00 0x3e200>;
			#interconnect-cells = <0x02>;
			qcom,bcm-voters = <0x5b>;
		};

		funnel@6045000 {
			clocks = <0x61>;
			compatible = "arm,coresight-dynamic-funnel", "arm,primecell";
			reg = <0x00 0x6045000 0x00 0x1000>;
			clock-names = "apb_pclk";
			status = "disabled";

			out-ports {

				port {

					endpoint {
						phandle = <0x79>;
						remote-endpoint = <0x72>;
					};
				};
			};

			in-ports {
				#address-cells = <0x01>;
				#size-cells = <0x00>;

				port@1 {
					reg = <0x01>;

					endpoint {
						phandle = <0x70>;
						remote-endpoint = <0x74>;
					};
				};

				port@0 {
					reg = <0x00>;

					endpoint {
						phandle = <0x6e>;
						remote-endpoint = <0x73>;
					};
				};
			};
		};

		sram@14680000 {
			compatible = "qcom,sc7180-imem", "syscon", "simple-mfd";
			reg = <0x00 0x14680000 0x00 0x2e000>;
			status = "disabled";
			#address-cells = <0x01>;
			#size-cells = <0x01>;
			ranges = <0x00 0x00 0x14680000 0x2e000>;

			pil-reloc@2a94c {
				compatible = "qcom,pil-reloc-info";
				reg = <0x2a94c 0xc8>;
			};
		};

		etm@7740000 {
			arm,coresight-loses-context-with-cpu;
			clocks = <0x61>;
			qcom,skip-power-up;
			cpu = <0x12>;
			compatible = "arm,coresight-etm4x", "arm,primecell";
			reg = <0x00 0x7740000 0x00 0x1000>;
			clock-names = "apb_pclk";
			status = "disabled";

			out-ports {

				port {

					endpoint {
						phandle = <0x8e>;
						remote-endpoint = <0x85>;
					};
				};
			};
		};

		sram@c3f0000 {
			compatible = "qcom,rpmh-stats";
			reg = <0x00 0xc3f0000 0x00 0x400>;
			status = "disabled";
		};

		replicator@6b06000 {
			qcom,replicator-loses-context;
			clocks = <0x61>;
			compatible = "arm,coresight-dynamic-replicator", "arm,primecell";
			reg = <0x00 0x6b06000 0x00 0x1000>;
			clock-names = "apb_pclk";
			status = "disabled";

			out-ports {

				port {

					endpoint {
						phandle = <0x76>;
						remote-endpoint = <0x7c>;
					};
				};
			};

			in-ports {

				port {

					endpoint {
						phandle = <0x7a>;
						remote-endpoint = <0x7d>;
					};
				};
			};
		};

		mailbox@17c00000 {
			phandle = <0x20>;
			compatible = "qcom,sc7180-apss-shared", "qcom,sdm845-apss-shared";
			reg = <0x00 0x17c00000 0x00 0x10000>;
			#mbox-cells = <0x01>;
		};

		lpass@62d87000 {
			interrupt-names = "lpass-irq-lpaif", "lpass-irq-hdmi";
			iommus = <0x25 0x1020 0x00 0x25 0x1021 0x00 0x25 0x1032 0x00>;
			clocks = <0x24 0x83 0xb8 0x06 0xb8 0x07 0xb8 0x0a 0xb8 0x08 0xb8 0x09>;
			required-opps = <0x15>;
			#sound-dai-cells = <0x01>;
			compatible = "qcom,sc7180-lpass-cpu";
			reg = <0x00 0x62d87000 0x00 0x68000 0x00 0x62f00000 0x00 0x29000>;
			clock-names = "pcnoc-sway-clk", "audio-core", "mclk0", "pcnoc-mport-clk", "mi2s-bit-clk0", "mi2s-bit-clk1";
			reg-names = "lpass-hdmiif", "lpass-lpaif";
			interrupts = <0x00 0xa0 0x04 0x00 0x10c 0x04>;
			status = "disabled";
			#address-cells = <0x01>;
			#size-cells = <0x00>;
			power-domains = <0xb7 0x00>;
		};

		pmu@90b6300 {
			operating-points-v2 = <0x99>;
			compatible = "qcom,sc7180-cpu-bwmon", "qcom,sdm845-bwmon";
			reg = <0x00 0x90b6300 0x00 0x600>;
			interrupts = <0x00 0x245 0x04>;
			status = "disabled";
			interconnects = <0x28 0x00 0x03 0x28 0x0b 0x03>;

			opp-table {
				phandle = <0x99>;
				compatible = "operating-points-v2";

				opp-2 {
					opp-peak-kBps = <0x6c7d70>;
				};

				opp-4 {
					opp-peak-kBps = <0xbba710>;
				};

				opp-0 {
					opp-peak-kBps = <0x22e980>;
				};

				opp-1 {
					opp-peak-kBps = <0x45d6e8>;
				};

				opp-3 {
					opp-peak-kBps = <0x8bb1b8>;
				};

				opp-5 {
					opp-peak-kBps = <0xd93960>;
				};
			};
		};

		phy@88e8000 {
			#phy-cells = <0x01>;
			vdda-phy-supply = <0x97>;
			clocks = <0x24 0x73 0x24 0x72 0x24 0x75 0x24 0x76 0x24 0x77>;
			phandle = <0x9c>;
			compatible = "qcom,sc7180-qmp-usb3-dp-phy";
			resets = <0x24 0x06 0x24 0x04>;
			reg = <0x00 0x88e8000 0x00 0x3000>;
			clock-names = "aux", "ref", "com_aux", "usb3_pipe", "cfg_ahb";
			status = "okay";
			#clock-cells = <0x01>;
			reset-names = "phy", "common";
			vdda-pll-supply = <0x94>;

			ports {
				#address-cells = <0x01>;
				#size-cells = <0x00>;

				port@2 {
					reg = <0x02>;

					endpoint {
					};
				};

				port@1 {
					reg = <0x01>;

					endpoint {
						phandle = <0x9d>;
						remote-endpoint = <0x98>;
					};
				};

				port@0 {
					reg = <0x00>;

					endpoint {
					};
				};
			};
		};

		interconnect@ac00000 {
			compatible = "qcom,sc7180-camnoc-virt";
			reg = <0x00 0xac00000 0x00 0x1000>;
			#interconnect-cells = <0x02>;
			status = "disabled";
			qcom,bcm-voters = <0x5b>;
		};

		hwlock@1f40000 {
			#hwlock-cells = <0x01>;
			phandle = <0x1f>;
			compatible = "qcom,tcsr-mutex";
			reg = <0x00 0x1f40000 0x00 0x20000>;
		};

		phy@1d87000 {
			#phy-cells = <0x00>;
			vdda-phy-supply = <0x94>;
			clocks = <0x21 0x00 0x24 0x67 0x24 0x61>;
			phandle = <0x5c>;
			compatible = "qcom,sc7180-qmp-ufs-phy";
			resets = <0x5e 0x00>;
			reg = <0x00 0x1d87000 0x00 0x1000>;
			clock-names = "ref", "ref_aux", "qref";
			status = "okay";
			power-domains = <0x24 0x00>;
			reset-names = "ufsphy";
			vdda-pll-supply = <0x97>;
		};

		interrupt-controller@17a00000 {
			interrupt-controller;
			phandle = <0x01>;
			compatible = "arm,gic-v3";
			reg = <0x00 0x17a00000 0x00 0x10000 0x00 0x17a60000 0x00 0x100000>;
			#interrupt-cells = <0x03>;
			#address-cells = <0x02>;
			#size-cells = <0x02>;
			ranges;

			msi-controller@17a40000 {
				msi-controller;
				#msi-cells = <0x01>;
				compatible = "arm,gic-v3-its";
				reg = <0x00 0x17a40000 0x00 0x20000>;
				status = "disabled";
			};
		};

		mmc@7c4000 {
			interrupt-names = "hc_irq", "pwr_irq";
			operating-points-v2 = <0x2a>;
			iommus = <0x25 0x60 0x00>;
			non-removable;
			interconnect-names = "sdhc-ddr", "cpu-sdhc";
			mmc-hs200-1_8v;
			supports-cqe;
			clocks = <0x24 0x58 0x24 0x59 0x21 0x00>;
			bus-width = <0x08>;
			mmc-hs400-1_8v;
			compatible = "qcom,sc7180-sdhci", "qcom,sdhci-msm-v5";
			reg = <0x00 0x7c4000 0x00 0x1000 0x00 0x7c5000 0x00 0x1000>;
			mmc-hs400-enhanced-strobe;
			clock-names = "iface", "core", "xo";
			reg-names = "hc", "cqhci";
			interrupts = <0x00 0x281 0x04 0x00 0x284 0x04>;
			status = "disabled";
			mmc-ddr-1_8v;
			power-domains = <0x23 0x00>;
			interconnects = <0x26 0x04 0x00 0x27 0x01 0x00 0x28 0x00 0x00 0x29 0x15 0x00>;

			opp-table {
				phandle = <0x2a>;
				compatible = "operating-points-v2";

				opp-384000000 {
					opp-hz = <0x00 0x16e36000>;
					required-opps = <0x15>;
					opp-avg-kBps = <0x5f370 0x00>;
					opp-peak-kBps = <0x5265c0 0x186a00>;
				};

				opp-100000000 {
					opp-hz = <0x00 0x5f5e100>;
					required-opps = <0x13>;
					opp-avg-kBps = <0x186a0 0x00>;
					opp-peak-kBps = <0x1b7740 0x927c0>;
				};
			};
		};

		reset-controller@b2e0000 {
			compatible = "qcom,sc7180-pdc-global", "qcom,sdm845-pdc-global";
			reg = <0x00 0xb2e0000 0x00 0x20000>;
			#reset-cells = <0x01>;
		};

		clock-controller@ab00000 {
			clocks = <0x21 0x00>;
			phandle = <0x9e>;
			#power-domain-cells = <0x01>;
			compatible = "qcom,sc7180-videocc";
			reg = <0x00 0xab00000 0x00 0x10000>;
			clock-names = "bi_tcxo";
			status = "okay";
			#clock-cells = <0x01>;
			#reset-cells = <0x01>;
		};

		watchdog@17c10000 {
			clocks = <0x22>;
			compatible = "qcom,apss-wdt-sc7180", "qcom,kpss-wdt";
			reg = <0x00 0x17c10000 0x00 0x1000>;
			interrupts = <0x00 0x00 0x01>;
			status = "disabled";
		};

		interconnect@1650000 {
			phandle = <0x2c>;
			compatible = "qcom,sc7180-qup-virt";
			reg = <0x00 0x1650000 0x00 0x1000>;
			#interconnect-cells = <0x02>;
			qcom,bcm-voters = <0x5b>;
		};

		funnel@7810000 {
			clocks = <0x61>;
			compatible = "arm,coresight-dynamic-funnel", "arm,primecell";
			reg = <0x00 0x7810000 0x00 0x1000>;
			clock-names = "apb_pclk";
			status = "disabled";

			out-ports {

				port {

					endpoint {
						phandle = <0x71>;
						remote-endpoint = <0x8f>;
					};
				};
			};

			in-ports {

				port {

					endpoint {
						phandle = <0x86>;
						remote-endpoint = <0x90>;
					};
				};
			};
		};

		interconnect@9990000 {
			compatible = "qcom,sc7180-npu-noc";
			reg = <0x00 0x9990000 0x00 0x1600>;
			#interconnect-cells = <0x02>;
			status = "disabled";
			qcom,bcm-voters = <0x5b>;
		};

		geniqup@ac0000 {
			iommus = <0x25 0x4c3 0x00>;
			clocks = <0x24 0x56 0x24 0x57>;
			compatible = "qcom,geni-se-qup";
			reg = <0x00 0xac0000 0x00 0x6000>;
			clock-names = "m-ahb", "s-ahb";
			status = "okay";
			#address-cells = <0x02>;
			#size-cells = <0x02>;
			ranges;

			serial@a90000 {
				operating-points-v2 = <0x2f>;
				interconnect-names = "qup-core", "qup-config";
				clocks = <0x24 0x50>;
				pinctrl-names = "default";
				pinctrl-0 = <0x56>;
				compatible = "qcom,geni-uart";
				reg = <0x00 0xa90000 0x00 0x4000>;
				clock-names = "se";
				interrupts = <0x00 0x165 0x04>;
				status = "disabled";
				power-domains = <0x23 0x00>;
				interconnects = <0x2c 0x01 0x00 0x2c 0x03 0x00 0x28 0x00 0x00 0x29 0x27 0x00>;
			};

			serial@a88000 {
				operating-points-v2 = <0x2f>;
				interconnect-names = "qup-core", "qup-config";
				clocks = <0x24 0x4c>;
				pinctrl-names = "default";
				pinctrl-0 = <0x50>;
				compatible = "qcom,geni-debug-uart";
				reg = <0x00 0xa88000 0x00 0x4000>;
				clock-names = "se";
				interrupts = <0x00 0x163 0x04>;
				status = "disabled";
				power-domains = <0x23 0x00>;
				interconnects = <0x2c 0x01 0x00 0x2c 0x03 0x00 0x28 0x00 0x00 0x29 0x27 0x00>;
			};

			serial@a84000 {
				operating-points-v2 = <0x2f>;
				interconnect-names = "qup-core", "qup-config";
				clocks = <0x24 0x4a>;
				pinctrl-names = "default";
				pinctrl-0 = <0x4c>;
				compatible = "qcom,geni-uart";
				reg = <0x00 0xa84000 0x00 0x4000>;
				clock-names = "se";
				interrupts = <0x00 0x162 0x04>;
				status = "disabled";
				power-domains = <0x23 0x00>;
				interconnects = <0x2c 0x01 0x00 0x2c 0x03 0x00 0x28 0x00 0x00 0x29 0x27 0x00>;
			};

			spi@a94000 {
				operating-points-v2 = <0x2f>;
				interconnect-names = "qup-core", "qup-config";
				clocks = <0x24 0x52>;
				pinctrl-names = "default";
				pinctrl-0 = <0x58 0x59>;
				compatible = "qcom,geni-spi";
				reg = <0x00 0xa94000 0x00 0x4000>;
				clock-names = "se";
				interrupts = <0x00 0x166 0x04>;
				status = "disabled";
				#address-cells = <0x01>;
				#size-cells = <0x00>;
				power-domains = <0x23 0x00>;
				interconnects = <0x2c 0x01 0x00 0x2c 0x03 0x00 0x28 0x00 0x00 0x29 0x27 0x00>;
			};

			spi@a80000 {
				operating-points-v2 = <0x2f>;
				interconnect-names = "qup-core", "qup-config";
				clocks = <0x24 0x48>;
				pinctrl-names = "default";
				pinctrl-0 = <0x48 0x49>;
				compatible = "qcom,geni-spi";
				reg = <0x00 0xa80000 0x00 0x4000>;
				clock-names = "se";
				interrupts = <0x00 0x161 0x04>;
				status = "disabled";
				#address-cells = <0x01>;
				#size-cells = <0x00>;
				power-domains = <0x23 0x00>;
				interconnects = <0x2c 0x01 0x00 0x2c 0x03 0x00 0x28 0x00 0x00 0x29 0x27 0x00>;
			};

			spi@a90000 {
				operating-points-v2 = <0x2f>;
				interconnect-names = "qup-core", "qup-config";
				clocks = <0x24 0x50>;
				pinctrl-names = "default";
				pinctrl-0 = <0x54 0x55>;
				compatible = "qcom,geni-spi";
				reg = <0x00 0xa90000 0x00 0x4000>;
				clock-names = "se";
				interrupts = <0x00 0x165 0x04>;
				status = "disabled";
				#address-cells = <0x01>;
				#size-cells = <0x00>;
				power-domains = <0x23 0x00>;
				interconnects = <0x2c 0x01 0x00 0x2c 0x03 0x00 0x28 0x00 0x00 0x29 0x27 0x00>;
			};

			i2c@a94000 {
				interconnect-names = "qup-core", "qup-config", "qup-memory";
				clocks = <0x24 0x52>;
				required-opps = <0x13>;
				pinctrl-names = "default";
				pinctrl-0 = <0x57>;
				compatible = "qcom,geni-i2c";
				reg = <0x00 0xa94000 0x00 0x4000>;
				clock-names = "se";
				interrupts = <0x00 0x166 0x04>;
				status = "disabled";
				#address-cells = <0x01>;
				#size-cells = <0x00>;
				power-domains = <0x23 0x00>;
				interconnects = <0x2c 0x01 0x00 0x2c 0x03 0x00 0x28 0x00 0x00 0x29 0x27 0x00 0x47 0x02 0x00 0x27 0x01 0x00>;
			};

			serial@a94000 {
				operating-points-v2 = <0x2f>;
				interconnect-names = "qup-core", "qup-config";
				clocks = <0x24 0x52>;
				pinctrl-names = "default";
				pinctrl-0 = <0x5a>;
				compatible = "qcom,geni-uart";
				reg = <0x00 0xa94000 0x00 0x4000>;
				clock-names = "se";
				interrupts = <0x00 0x166 0x04>;
				status = "disabled";
				power-domains = <0x23 0x00>;
				interconnects = <0x2c 0x01 0x00 0x2c 0x03 0x00 0x28 0x00 0x00 0x29 0x27 0x00>;
			};

			i2c@a88000 {
				interconnect-names = "qup-core", "qup-config", "qup-memory";
				clocks = <0x24 0x4c>;
				required-opps = <0x13>;
				pinctrl-names = "default";
				pinctrl-0 = <0x4d>;
				compatible = "qcom,geni-i2c";
				reg = <0x00 0xa88000 0x00 0x4000>;
				clock-names = "se";
				interrupts = <0x00 0x163 0x04>;
				status = "disabled";
				#address-cells = <0x01>;
				#size-cells = <0x00>;
				power-domains = <0x23 0x00>;
				interconnects = <0x2c 0x01 0x00 0x2c 0x03 0x00 0x28 0x00 0x00 0x29 0x27 0x00 0x47 0x02 0x00 0x27 0x01 0x00>;
			};

			spi@a88000 {
				operating-points-v2 = <0x2f>;
				interconnect-names = "qup-core", "qup-config";
				clocks = <0x24 0x4c>;
				pinctrl-names = "default";
				pinctrl-0 = <0x4e 0x4f>;
				compatible = "qcom,geni-spi";
				reg = <0x00 0xa88000 0x00 0x4000>;
				clock-names = "se";
				interrupts = <0x00 0x163 0x04>;
				status = "disabled";
				#address-cells = <0x01>;
				#size-cells = <0x00>;
				power-domains = <0x23 0x00>;
				interconnects = <0x2c 0x01 0x00 0x2c 0x03 0x00 0x28 0x00 0x00 0x29 0x27 0x00>;
			};

			i2c@a84000 {
				interconnect-names = "qup-core", "qup-config", "qup-memory";
				clocks = <0x24 0x4a>;
				required-opps = <0x13>;
				pinctrl-names = "default";
				pinctrl-0 = <0x4b>;
				compatible = "qcom,geni-i2c";
				reg = <0x00 0xa84000 0x00 0x4000>;
				clock-names = "se";
				interrupts = <0x00 0x162 0x04>;
				status = "disabled";
				#address-cells = <0x01>;
				#size-cells = <0x00>;
				power-domains = <0x23 0x00>;
				interconnects = <0x2c 0x01 0x00 0x2c 0x03 0x00 0x28 0x00 0x00 0x29 0x27 0x00 0x47 0x02 0x00 0x27 0x01 0x00>;
			};

			i2c@a8c000 {
				interconnect-names = "qup-core", "qup-config", "qup-memory";
				clocks = <0x24 0x4e>;
				required-opps = <0x13>;
				pinctrl-names = "default";
				pinctrl-0 = <0x51>;
				compatible = "qcom,geni-i2c";
				reg = <0x00 0xa8c000 0x00 0x4000>;
				clock-names = "se";
				interrupts = <0x00 0x164 0x04>;
				status = "disabled";
				#address-cells = <0x01>;
				#size-cells = <0x00>;
				power-domains = <0x23 0x00>;
				interconnects = <0x2c 0x01 0x00 0x2c 0x03 0x00 0x28 0x00 0x00 0x29 0x27 0x00 0x47 0x02 0x00 0x27 0x01 0x00>;
			};

			i2c@a90000 {
				interconnect-names = "qup-core", "qup-config", "qup-memory";
				clocks = <0x24 0x50>;
				required-opps = <0x13>;
				pinctrl-names = "default";
				pinctrl-0 = <0x53>;
				compatible = "qcom,geni-i2c";
				reg = <0x00 0xa90000 0x00 0x4000>;
				clock-names = "se";
				interrupts = <0x00 0x165 0x04>;
				status = "okay";
				#address-cells = <0x01>;
				clock-frequency = <0x186a0>;
				#size-cells = <0x00>;
				power-domains = <0x23 0x00>;
				interconnects = <0x2c 0x01 0x00 0x2c 0x03 0x00 0x28 0x00 0x00 0x29 0x27 0x00 0x47 0x02 0x00 0x27 0x01 0x00>;

				bridge@29 {
					compatible = "tcl,b220g-lt8911exb-handoff-test";
					reg = <0x29>;

					port {

						endpoint {
							data-lanes = <0x00 0x01 0x02 0x03>;
							phandle = <0xbf>;
							remote-endpoint = <0xbc>;
						};
					};
				};
			};

			serial@a8c000 {
				operating-points-v2 = <0x2f>;
				interconnect-names = "qup-core", "qup-config";
				clocks = <0x24 0x4e>;
				pinctrl-names = "default";
				pinctrl-0 = <0x52>;
				compatible = "qcom,geni-uart";
				reg = <0x00 0xa8c000 0x00 0x4000>;
				clock-names = "se";
				interrupts = <0x00 0x164 0x04>;
				status = "disabled";
				power-domains = <0x23 0x00>;
				interconnects = <0x2c 0x01 0x00 0x2c 0x03 0x00 0x28 0x00 0x00 0x29 0x27 0x00>;
			};

			i2c@a80000 {
				interconnect-names = "qup-core", "qup-config", "qup-memory";
				clocks = <0x24 0x48>;
				required-opps = <0x13>;
				pinctrl-names = "default";
				pinctrl-0 = <0x46>;
				compatible = "qcom,geni-i2c";
				reg = <0x00 0xa80000 0x00 0x4000>;
				clock-names = "se";
				interrupts = <0x00 0x161 0x04>;
				status = "disabled";
				#address-cells = <0x01>;
				#size-cells = <0x00>;
				power-domains = <0x23 0x00>;
				interconnects = <0x2c 0x01 0x00 0x2c 0x03 0x00 0x28 0x00 0x00 0x29 0x27 0x00 0x47 0x02 0x00 0x27 0x01 0x00>;
			};

			serial@a80000 {
				operating-points-v2 = <0x2f>;
				interconnect-names = "qup-core", "qup-config";
				clocks = <0x24 0x48>;
				pinctrl-names = "default";
				pinctrl-0 = <0x4a>;
				compatible = "qcom,geni-uart";
				reg = <0x00 0xa80000 0x00 0x4000>;
				clock-names = "se";
				interrupts = <0x00 0x161 0x04>;
				status = "disabled";
				power-domains = <0x23 0x00>;
				interconnects = <0x2c 0x01 0x00 0x2c 0x03 0x00 0x28 0x00 0x00 0x29 0x27 0x00>;
			};
		};

		interconnect@1620000 {
			phandle = <0x60>;
			compatible = "qcom,sc7180-system-noc";
			reg = <0x00 0x1620000 0x00 0x17080>;
			#interconnect-cells = <0x02>;
			qcom,bcm-voters = <0x5b>;
		};

		etr@6048000 {
			iommus = <0x25 0x4a0 0x20>;
			arm,scatter-gather;
			clocks = <0x61>;
			compatible = "arm,coresight-tmc", "arm,primecell";
			reg = <0x00 0x6048000 0x00 0x1000>;
			clock-names = "apb_pclk";
			status = "disabled";

			in-ports {

				port {

					endpoint {
						phandle = <0x75>;
						remote-endpoint = <0x77>;
					};
				};
			};
		};

		pinctrl@627c0000 {
			gpio-ranges = <0xdf 0x00 0x00 0x0f>;
			#gpio-cells = <0x02>;
			gpio-controller;
			clocks = <0xda 0x66 0x01 0xda 0x67 0x01>;
			phandle = <0xdf>;
			compatible = "qcom,sc7280-lpass-lpi-pinctrl";
			reg = <0x00 0x627c0000 0x00 0x10000 0x00 0x62950000 0x00 0x10000>;
			clock-names = "core", "audio";

			rx-data-state {
				phandle = <0xe1>;
				drive-strength = <0x0a>;
				function = "swr_rx_data";
				bias-bus-hold;
				slew-rate = <0x03>;
				pins = "gpio4", "gpio5";
			};

			rx-clock-state {
				phandle = <0xe0>;
				drive-strength = <0x0a>;
				function = "swr_rx_clk";
				slew-rate = <0x03>;
				pins = "gpio3";
				bias-disable;
			};
		};

		etm@7640000 {
			arm,coresight-loses-context-with-cpu;
			clocks = <0x61>;
			qcom,skip-power-up;
			cpu = <0x11>;
			compatible = "arm,coresight-etm4x", "arm,primecell";
			reg = <0x00 0x7640000 0x00 0x1000>;
			clock-names = "apb_pclk";
			status = "disabled";

			out-ports {

				port {

					endpoint {
						phandle = <0x8d>;
						remote-endpoint = <0x84>;
					};
				};
			};
		};

		funnel@6042000 {
			clocks = <0x61>;
			compatible = "arm,coresight-dynamic-funnel", "arm,primecell";
			reg = <0x00 0x6042000 0x00 0x1000>;
			clock-names = "apb_pclk";
			status = "disabled";

			out-ports {

				port {

					endpoint {
						phandle = <0x74>;
						remote-endpoint = <0x70>;
					};
				};
			};

			in-ports {
				#address-cells = <0x01>;
				#size-cells = <0x00>;

				port@4 {
					reg = <0x04>;

					endpoint {
						phandle = <0x8f>;
						remote-endpoint = <0x71>;
					};
				};
			};
		};

		cpufreq@18323000 {
			clocks = <0x21 0x00 0x24 0x01>;
			phandle = <0xbb>;
			#freq-domain-cells = <0x01>;
			compatible = "qcom,sc7180-cpufreq-hw", "qcom,cpufreq-hw";
			reg = <0x00 0x18323000 0x00 0x1400 0x00 0x18325800 0x00 0x1400>;
			clock-names = "xo", "alternate";
			reg-names = "freq-domain0", "freq-domain1";
			status = "okay";
			#clock-cells = <0x01>;
		};

		system-cache-controller@9200000 {
			compatible = "qcom,sc7180-llcc";
			reg = <0x00 0x9200000 0x00 0x50000 0x00 0x9600000 0x00 0x50000>;
			reg-names = "llcc0_base", "llcc_broadcast_base";
			interrupts = <0x00 0x246 0x04>;
			status = "disabled";
		};

		clock-controller@62d00000 {
			clocks = <0x24 0x83 0x21 0x00>;
			phandle = <0xb8>;
			#power-domain-cells = <0x01>;
			compatible = "qcom,sc7180-lpasscorecc";
			reg = <0x00 0x62d00000 0x00 0x50000 0x00 0x62780000 0x00 0x30000>;
			clock-names = "iface", "bi_tcxo";
			reg-names = "lpass_core_cc", "lpass_audio_cc";
			status = "disabled";
			#clock-cells = <0x01>;
			power-domains = <0xb7 0x00>;
		};

		usb@a6f8800 {
			interrupt-names = "pwr_event", "hs_phy_irq", "dp_hs_phy_irq", "dm_hs_phy_irq", "ss_phy_irq";
			assigned-clock-rates = <0x124f800 0x8f0d180>;
			interconnect-names = "usb-ddr", "apps-usb";
			interrupts-extended = <0x01 0x00 0x82 0x04 0x01 0x00 0x83 0x04 0x63 0x09 0x03 0x63 0x08 0x03 0x63 0x06 0x04>;
			clocks = <0x24 0x11 0x24 0x6d 0x24 0x08 0x24 0x71 0x24 0x6f>;
			required-opps = <0x15>;
			wakeup-source;
			compatible = "qcom,sc7180-dwc3", "qcom,dwc3";
			resets = <0x24 0x03>;
			reg = <0x00 0xa6f8800 0x00 0x400>;
			clock-names = "cfg_noc", "core", "iface", "sleep", "mock_utmi";
			status = "okay";
			#address-cells = <0x02>;
			assigned-clocks = <0x24 0x6f 0x24 0x6d>;
			#size-cells = <0x02>;
			power-domains = <0x24 0x01>;
			interconnects = <0x47 0x03 0x00 0x27 0x01 0x00 0x28 0x00 0x00 0x29 0x30 0x00>;
			dma-ranges;
			ranges;

			usb@a600000 {
				iommus = <0x25 0x540 0x00>;
				phy-names = "usb2-phy", "usb3-phy";
				snps,dis_enblslpm_quirk;
				compatible = "snps,dwc3";
				maximum-speed = "super-speed";
				reg = <0x00 0xa600000 0x00 0xe000>;
				snps,parkmode-disable-ss-quirk;
				snps,dis-u2-entry-quirk;
				interrupts = <0x00 0x85 0x04>;
				snps,dis_u2_susphy_quirk;
				dr_mode = "host";
				phys = <0x9b 0x9c 0x00>;
				snps,dis-u1-entry-quirk;

				ports {
					#address-cells = <0x01>;
					#size-cells = <0x00>;

					port@1 {
						reg = <0x01>;

						endpoint {
							phandle = <0x98>;
							remote-endpoint = <0x9d>;
						};
					};

					port@0 {
						reg = <0x00>;

						endpoint {
						};
					};
				};
			};
		};

		ufshc@1d84000 {
			iommus = <0x25 0xa0 0x00>;
			interconnect-names = "ufs-ddr", "cpu-ufs";
			phy-names = "ufsphy";
			clocks = <0x24 0x63 0x24 0x07 0x24 0x62 0x24 0x6b 0x21 0x00 0x24 0x6a 0x24 0x69>;
			phandle = <0x5e>;
			vccq2-supply = <0xb9>;
			compatible = "qcom,sc7180-ufshc", "qcom,ufshc", "jedec,ufs-2.0";
			resets = <0x24 0x02>;
			freq-table-hz = <0x2faf080 0xbebc200 0x00 0x00 0x00 0x00 0x23c3460 0x8f0d180 0x00 0x00 0x00 0x00 0x00 0x00>;
			reg = <0x00 0x1d84000 0x00 0x3000>;
			clock-names = "core_clk", "bus_aggr_clk", "iface_clk", "core_clk_unipro", "ref_clk", "tx_lane0_sync_clk", "rx_lane0_sync_clk";
			lanes-per-direction = <0x01>;
			interrupts = <0x00 0x109 0x04>;
			status = "okay";
			qcom,ice = <0x5d>;
			phys = <0x5c>;
			power-domains = <0x24 0x00>;
			interconnects = <0x26 0x05 0x07 0x27 0x01 0x07 0x28 0x00 0x07 0x29 0x2f 0x07>;
			reset-names = "rst";
			#reset-cells = <0x01>;
			vcc-supply = <0xba>;
		};

		etm@7140000 {
			arm,coresight-loses-context-with-cpu;
			clocks = <0x61>;
			qcom,skip-power-up;
			cpu = <0x0c>;
			compatible = "arm,coresight-etm4x", "arm,primecell";
			reg = <0x00 0x7140000 0x00 0x1000>;
			clock-names = "apb_pclk";
			status = "disabled";

			out-ports {

				port {

					endpoint {
						phandle = <0x88>;
						remote-endpoint = <0x7f>;
					};
				};
			};
		};

		clock-controller@ad00000 {
			clocks = <0x21 0x00 0x24 0x0a 0x24 0x0d>;
			#power-domain-cells = <0x01>;
			compatible = "qcom,sc7180-camcc";
			reg = <0x00 0xad00000 0x00 0x10000>;
			clock-names = "bi_tcxo", "iface", "xo";
			status = "disabled";
			#clock-cells = <0x01>;
			#reset-cells = <0x01>;
		};

		clock-controller@af00000 {
			clocks = <0x21 0x00 0x24 0x18 0xa8 0x00 0xa8 0x01 0x9c 0x01 0x9c 0x02>;
			phandle = <0xa3>;
			#power-domain-cells = <0x01>;
			compatible = "qcom,sc7180-dispcc";
			reg = <0x00 0xaf00000 0x00 0x200000>;
			clock-names = "bi_tcxo", "gcc_disp_gpll0_clk_src", "dsi0_phy_pll_out_byteclk", "dsi0_phy_pll_out_dsiclk", "dp_phy_pll_link_clk", "dp_phy_pll_vco_div_clk";
			status = "okay";
			#clock-cells = <0x01>;
			#reset-cells = <0x01>;
		};

		funnel@7800000 {
			clocks = <0x61>;
			compatible = "arm,coresight-dynamic-funnel", "arm,primecell";
			reg = <0x00 0x7800000 0x00 0x1000>;
			clock-names = "apb_pclk";
			status = "disabled";

			out-ports {

				port {

					endpoint {
						phandle = <0x90>;
						remote-endpoint = <0x86>;
					};
				};
			};

			in-ports {
				#address-cells = <0x01>;
				#size-cells = <0x00>;

				port@4 {
					reg = <0x04>;

					endpoint {
						phandle = <0x82>;
						remote-endpoint = <0x8b>;
					};
				};

				port@2 {
					reg = <0x02>;

					endpoint {
						phandle = <0x80>;
						remote-endpoint = <0x89>;
					};
				};

				port@6 {
					reg = <0x06>;

					endpoint {
						phandle = <0x84>;
						remote-endpoint = <0x8d>;
					};
				};

				port@7 {
					reg = <0x07>;

					endpoint {
						phandle = <0x85>;
						remote-endpoint = <0x8e>;
					};
				};

				port@1 {
					reg = <0x01>;

					endpoint {
						phandle = <0x7f>;
						remote-endpoint = <0x88>;
					};
				};

				port@3 {
					reg = <0x03>;

					endpoint {
						phandle = <0x81>;
						remote-endpoint = <0x8a>;
					};
				};

				port@5 {
					reg = <0x05>;

					endpoint {
						phandle = <0x83>;
						remote-endpoint = <0x8c>;
					};
				};

				port@0 {
					reg = <0x00>;

					endpoint {
						phandle = <0x7e>;
						remote-endpoint = <0x87>;
					};
				};
			};
		};

		iommu@15000000 {
			phandle = <0x25>;
			#global-interrupts = <0x01>;
			#iommu-cells = <0x02>;
			compatible = "qcom,sc7180-smmu-500", "arm,mmu-500";
			reg = <0x00 0x15000000 0x00 0x100000>;
			dma-coherent;
			interrupts = <0x00 0x41 0x04 0x00 0x5e 0x04 0x00 0x5f 0x04 0x00 0x60 0x04 0x00 0x61 0x04 0x00 0x62 0x04 0x00 0x63 0x04 0x00 0x64 0x04 0x00 0x65 0x04 0x00 0x66 0x04 0x00 0x67 0x04 0x00 0x68 0x04 0x00 0x69 0x04 0x00 0x6a 0x04 0x00 0x6b 0x04 0x00 0x6c 0x04 0x00 0x6d 0x04 0x00 0x6e 0x04 0x00 0x6f 0x04 0x00 0x70 0x04 0x00 0x71 0x04 0x00 0x72 0x04 0x00 0x73 0x04 0x00 0x74 0x04 0x00 0x75 0x04 0x00 0x76 0x04 0x00 0xb5 0x04 0x00 0xb6 0x04 0x00 0xb7 0x04 0x00 0xb8 0x04 0x00 0xb9 0x04 0x00 0xba 0x04 0x00 0xbb 0x04 0x00 0xbc 0x04 0x00 0xbd 0x04 0x00 0xbe 0x04 0x00 0xbf 0x04 0x00 0xc0 0x04 0x00 0x13b 0x04 0x00 0x13c 0x04 0x00 0x13d 0x04 0x00 0x13e 0x04 0x00 0x13f 0x04 0x00 0x140 0x04 0x00 0x141 0x04 0x00 0x142 0x04 0x00 0x143 0x04 0x00 0x144 0x04 0x00 0x145 0x04 0x00 0x146 0x04 0x00 0x147 0x04 0x00 0x148 0x04 0x00 0x149 0x04 0x00 0x14a 0x04 0x00 0x14b 0x04 0x00 0x14c 0x04 0x00 0x14d 0x04 0x00 0x14e 0x04 0x00 0x14f 0x04 0x00 0x150 0x04 0x00 0x151 0x04 0x00 0x152 0x04 0x00 0x153 0x04 0x00 0x154 0x04 0x00 0x155 0x04 0x00 0x156 0x04 0x00 0x157 0x04 0x00 0x158 0x04 0x00 0x159 0x04 0x00 0x191 0x04 0x00 0x192 0x04 0x00 0x193 0x04 0x00 0x194 0x04 0x00 0x195 0x04 0x00 0x196 0x04 0x00 0x197 0x04 0x00 0x198 0x04 0x00 0x199 0x04 0x00 0x19a 0x04 0x00 0x19b 0x04 0x00 0x19c 0x04>;
		};

		etm@7040000 {
			arm,coresight-loses-context-with-cpu;
			clocks = <0x61>;
			qcom,skip-power-up;
			cpu = <0x0b>;
			compatible = "arm,coresight-etm4x", "arm,primecell";
			reg = <0x00 0x7040000 0x00 0x1000>;
			clock-names = "apb_pclk";
			status = "disabled";

			out-ports {

				port {

					endpoint {
						phandle = <0x87>;
						remote-endpoint = <0x7e>;
					};
				};
			};
		};

		replicator@6046000 {
			clocks = <0x61>;
			compatible = "arm,coresight-dynamic-replicator", "arm,primecell";
			reg = <0x00 0x6046000 0x00 0x1000>;
			clock-names = "apb_pclk";
			status = "disabled";

			out-ports {

				port {

					endpoint {
						phandle = <0x77>;
						remote-endpoint = <0x75>;
					};
				};
			};

			in-ports {

				port {

					endpoint {
						phandle = <0x7c>;
						remote-endpoint = <0x76>;
					};
				};
			};
		};

		syscon@1fc0000 {
			compatible = "qcom,sc7180-tcsr", "syscon";
			reg = <0x00 0x1fc0000 0x00 0x40000>;
		};

		etm@7540000 {
			arm,coresight-loses-context-with-cpu;
			clocks = <0x61>;
			qcom,skip-power-up;
			cpu = <0x10>;
			compatible = "arm,coresight-etm4x", "arm,primecell";
			reg = <0x00 0x7540000 0x00 0x1000>;
			clock-names = "apb_pclk";
			status = "disabled";

			out-ports {

				port {

					endpoint {
						phandle = <0x8c>;
						remote-endpoint = <0x83>;
					};
				};
			};
		};

		interrupt-controller@b220000 {
			interrupt-controller;
			phandle = <0x63>;
			qcom,pdc-ranges = <0x00 0x1e0 0x5e 0x5e 0x261 0x1f 0x7d 0x3f 0x01>;
			compatible = "qcom,sc7180-pdc", "qcom,pdc";
			reg = <0x00 0xb220000 0x00 0x30000>;
			#interrupt-cells = <0x02>;
			interrupt-parent = <0x01>;
		};

		interconnect@18321000 {
			clocks = <0x21 0x00 0x24 0x01>;
			compatible = "qcom,sc7180-osm-l3", "qcom,osm-l3";
			reg = <0x00 0x18321000 0x00 0x1400>;
			clock-names = "xo", "alternate";
			#interconnect-cells = <0x01>;
			status = "disabled";
		};

		display-subsystem@ae00000 {
			iommus = <0x25 0x800 0x02>;
			interconnect-names = "mdp0-mem", "cpu-cfg";
			clocks = <0x24 0x17 0xa3 0x02 0xa3 0x14>;
			interrupt-controller;
			phandle = <0xa5>;
			compatible = "qcom,sc7180-mdss";
			reg = <0x00 0xae00000 0x00 0x1000>;
			#interrupt-cells = <0x01>;
			clock-names = "iface", "ahb", "core";
			reg-names = "mdss";
			interrupts = <0x00 0x53 0x04>;
			status = "okay";
			#address-cells = <0x02>;
			#size-cells = <0x02>;
			power-domains = <0xa3 0x00>;
			interconnects = <0xa0 0x04 0x07 0x27 0x01 0x07 0x28 0x00 0x07 0x29 0x12 0x07>;
			ranges;

			phy@ae94400 {
				#phy-cells = <0x00>;
				clocks = <0xa3 0x02 0x21 0x00>;
				vdds-supply = <0x94>;
				phandle = <0xa8>;
				compatible = "qcom,dsi-phy-10nm";
				reg = <0x00 0xae94400 0x00 0x200 0x00 0xae94600 0x00 0x280 0x00 0xae94a00 0x00 0x1e0>;
				clock-names = "iface", "ref";
				reg-names = "dsi_phy", "dsi_phy_lane", "dsi_pll";
				status = "okay";
				#clock-cells = <0x01>;
			};

			displayport-controller@ae90000 {
				operating-points-v2 = <0xab>;
				assigned-clock-parents = <0x9c 0x01 0x9c 0x02>;
				phy-names = "dp";
				clocks = <0xa3 0x02 0xa3 0x08 0xa3 0x0c 0xa3 0x0f 0xa3 0x10>;
				#sound-dai-cells = <0x00>;
				compatible = "qcom,sc7180-dp";
				reg = <0x00 0xae90000 0x00 0x200 0x00 0xae90200 0x00 0x200 0x00 0xae90400 0x00 0xc00 0x00 0xae91000 0x00 0x400 0x00 0xae91400 0x00 0x400>;
				clock-names = "core_iface", "core_aux", "ctrl_link", "ctrl_link_iface", "stream_pixel";
				interrupt-parent = <0xa5>;
				interrupts = <0x0c>;
				status = "disabled";
				assigned-clocks = <0xa3 0x0d 0xa3 0x11>;
				phys = <0x9c 0x01>;
				power-domains = <0x23 0x00>;

				ports {
					#address-cells = <0x01>;
					#size-cells = <0x00>;

					port@1 {
						reg = <0x01>;

						endpoint {
						};
					};

					port@0 {
						reg = <0x00>;

						endpoint {
							phandle = <0xa7>;
							remote-endpoint = <0xac>;
						};
					};
				};

				opp-table {
					phandle = <0xab>;
					compatible = "operating-points-v2";

					opp-160000000 {
						opp-hz = <0x00 0x9896800>;
						required-opps = <0x13>;
					};

					opp-540000000 {
						opp-hz = <0x00 0x202fbf00>;
						required-opps = <0xa1>;
					};

					opp-270000000 {
						opp-hz = <0x00 0x1017df80>;
						required-opps = <0x14>;
					};

					opp-810000000 {
						opp-hz = <0x00 0x30479e80>;
						required-opps = <0x15>;
					};
				};
			};

			dsi@ae94000 {
				operating-points-v2 = <0xa9>;
				assigned-clock-parents = <0xa8 0x00 0xa8 0x01>;
				clocks = <0xa3 0x04 0xa3 0x07 0xa3 0x18 0xa3 0x12 0xa3 0x02 0x24 0x1a>;
				compatible = "qcom,sc7180-dsi-ctrl", "qcom,mdss-dsi-ctrl";
				reg = <0x00 0xae94000 0x00 0x400>;
				clock-names = "byte", "byte_intf", "pixel", "core", "iface", "bus";
				reg-names = "dsi_ctrl";
				interrupt-parent = <0xa5>;
				interrupts = <0x04>;
				status = "okay";
				#address-cells = <0x01>;
				vdda-supply = <0x97>;
				assigned-clocks = <0xa3 0x05 0xa3 0x19>;
				#size-cells = <0x00>;
				phys = <0xa8>;
				power-domains = <0x23 0x00>;

				ports {
					#address-cells = <0x01>;
					#size-cells = <0x00>;

					port@1 {
						reg = <0x01>;

						endpoint {
							data-lanes = <0x00 0x01 0x02 0x03>;
							phandle = <0xbc>;
							remote-endpoint = <0xbf>;
						};
					};

					port@0 {
						reg = <0x00>;

						endpoint {
							phandle = <0xa6>;
							remote-endpoint = <0xaa>;
						};
					};
				};

				opp-table {
					phandle = <0xa9>;
					compatible = "operating-points-v2";

					opp-187500000 {
						opp-hz = <0x00 0xb2d05e0>;
						required-opps = <0x13>;
					};

					opp-300000000 {
						opp-hz = <0x00 0x11e1a300>;
						required-opps = <0x14>;
					};

					opp-358000000 {
						opp-hz = <0x00 0x1556a580>;
						required-opps = <0xa1>;
					};
				};
			};

			display-controller@ae01000 {
				operating-points-v2 = <0xa4>;
				assigned-clock-rates = <0x124f800 0x124f800 0x124f800>;
				clocks = <0x24 0x1a 0xa3 0x02 0xa3 0x1a 0xa3 0x16 0xa3 0x14 0xa3 0x1e>;
				compatible = "qcom,sc7180-dpu";
				reg = <0x00 0xae01000 0x00 0x8f000 0x00 0xaeb0000 0x00 0x3000>;
				clock-names = "bus", "iface", "rot", "lut", "core", "vsync";
				reg-names = "mdp", "vbif";
				interrupt-parent = <0xa5>;
				interrupts = <0x00>;
				assigned-clocks = <0xa3 0x1e 0xa3 0x1a 0xa3 0x02>;
				power-domains = <0x23 0x00>;

				ports {
					#address-cells = <0x01>;
					#size-cells = <0x00>;

					port@2 {
						reg = <0x02>;

						endpoint {
							phandle = <0xac>;
							remote-endpoint = <0xa7>;
						};
					};

					port@0 {
						reg = <0x00>;

						endpoint {
							phandle = <0xaa>;
							remote-endpoint = <0xa6>;
						};
					};
				};

				opp-table {
					phandle = <0xa4>;
					compatible = "operating-points-v2";

					opp-345000000 {
						opp-hz = <0x00 0x14904840>;
						required-opps = <0xa1>;
					};

					opp-460000000 {
						opp-hz = <0x00 0x1b6b0b00>;
						required-opps = <0x15>;
					};

					opp-300000000 {
						opp-hz = <0x00 0x11e1a300>;
						required-opps = <0x14>;
					};

					opp-200000000 {
						opp-hz = <0x00 0xbebc200>;
						required-opps = <0x13>;
					};
				};
			};
		};

		etm@7440000 {
			arm,coresight-loses-context-with-cpu;
			clocks = <0x61>;
			qcom,skip-power-up;
			cpu = <0x0f>;
			compatible = "arm,coresight-etm4x", "arm,primecell";
			reg = <0x00 0x7440000 0x00 0x1000>;
			clock-names = "apb_pclk";
			status = "disabled";

			out-ports {

				port {

					endpoint {
						phandle = <0x8b>;
						remote-endpoint = <0x82>;
					};
				};
			};
		};

		rx-pin-test {
			pinctrl-names = "default";
			pinctrl-0 = <0xe0 0xe1>;
			compatible = "tcl,rx-pin-test";
		};

		clock-controller@63000000 {
			clocks = <0x24 0x83 0x21 0x00>;
			phandle = <0xb7>;
			#power-domain-cells = <0x01>;
			compatible = "qcom,sc7180-lpasshm";
			reg = <0x00 0x63000000 0x00 0x28>;
			clock-names = "iface", "bi_tcxo";
			status = "disabled";
			#clock-cells = <0x01>;
			power-domains = <0x23 0x00>;
		};

		pmu@90cd000 {
			operating-points-v2 = <0x9a>;
			compatible = "qcom,sc7180-llcc-bwmon", "qcom,sc7280-llcc-bwmon";
			reg = <0x00 0x90cd000 0x00 0x1000>;
			interrupts = <0x00 0xf1 0x04>;
			status = "disabled";
			interconnects = <0x27 0x00 0x03 0x27 0x01 0x03>;

			opp-table {
				phandle = <0x9a>;
				compatible = "operating-points-v2";

				opp-2 {
					opp-peak-kBps = <0x1fd470>;
				};

				opp-4 {
					opp-peak-kBps = <0x3b3058>;
				};

				opp-0 {
					opp-peak-kBps = <0x1174c0>;
				};

				opp-1 {
					opp-peak-kBps = <0x1a3ec0>;
				};

				opp-6 {
					opp-peak-kBps = <0x68fee8>;
				};

				opp-3 {
					opp-peak-kBps = <0x2cb168>;
				};

				opp-7 {
					opp-peak-kBps = <0x7c2928>;
				};

				opp-5 {
					opp-peak-kBps = <0x5a7ff8>;
				};
			};
		};

		etf@6b05000 {
			clocks = <0x61>;
			compatible = "arm,coresight-tmc", "arm,primecell";
			reg = <0x00 0x6b05000 0x00 0x1000>;
			clock-names = "apb_pclk";
			status = "disabled";

			out-ports {

				port {

					endpoint {
						phandle = <0x7d>;
						remote-endpoint = <0x7a>;
					};
				};
			};

			in-ports {

				port {

					endpoint {
						phandle = <0x78>;
						remote-endpoint = <0x7b>;
					};
				};
			};
		};

		etm@7240000 {
			arm,coresight-loses-context-with-cpu;
			clocks = <0x61>;
			qcom,skip-power-up;
			cpu = <0x0d>;
			compatible = "arm,coresight-etm4x", "arm,primecell";
			reg = <0x00 0x7240000 0x00 0x1000>;
			clock-names = "apb_pclk";
			status = "disabled";

			out-ports {

				port {

					endpoint {
						phandle = <0x89>;
						remote-endpoint = <0x80>;
					};
				};
			};
		};

		funnel@6b04000 {
			clocks = <0x61>;
			compatible = "arm,coresight-dynamic-funnel", "arm,primecell";
			reg = <0x00 0x6b04000 0x00 0x1000>;
			clock-names = "apb_pclk";
			status = "disabled";

			out-ports {

				port {

					endpoint {
						phandle = <0x7b>;
						remote-endpoint = <0x78>;
					};
				};
			};

			in-ports {
				#address-cells = <0x01>;
				#size-cells = <0x00>;

				port@7 {
					reg = <0x07>;

					endpoint {
						phandle = <0x72>;
						remote-endpoint = <0x79>;
					};
				};
			};
		};

		phy@88e3000 {
			#phy-cells = <0x00>;
			vdda-phy-dpdm-supply = <0x96>;
			vdd-supply = <0x94>;
			clocks = <0x24 0x77 0x21 0x00>;
			phandle = <0x9b>;
			compatible = "qcom,sc7180-qusb2-phy", "qcom,qusb2-v2-phy";
			resets = <0x24 0x00>;
			nvmem-cells = <0x93>;
			reg = <0x00 0x88e3000 0x00 0x400>;
			clock-names = "cfg_ahb", "ref";
			status = "okay";
			vdda-pll-supply = <0x95>;
		};

		soundwire@62610000 {
			qcom,ports-word-length = [01 07 04 ff ff];
			qcom,ports-hstop = [ff 06 ff ff ff];
			qcom,din-ports = <0x00>;
			clocks = <0xdd>;
			qcom,ports-offset1 = [00 00 0b 01 00];
			#sound-dai-cells = <0x01>;
			qcom,ports-offset2 = [00 00 0b 00 00];
			compatible = "qcom,soundwire-v1.5.1";
			reg = <0x00 0x62610000 0x00 0x2000>;
			qcom,ports-block-pack-mode = [ff 00 01 ff ff];
			clock-names = "iface";
			qcom,ports-hstart = [ff 03 ff ff ff];
			qcom,ports-lane-control = [01 00 00 00 00];
			interrupts = <0x00 0x129 0x01>;
			status = "okay";
			#address-cells = <0x02>;
			label = "RX";
			qcom,ports-sinterval-low = [03 1f 1f 07 00];
			#size-cells = <0x00>;
			qcom,ports-block-group-count = [ff ff ff ff 00];
			qcom,dout-ports = <0x05>;
		};

		clock-controller@5090000 {
			clocks = <0x21 0x00 0x24 0x24 0x24 0x25>;
			phandle = <0x6b>;
			#power-domain-cells = <0x01>;
			compatible = "qcom,sc7180-gpucc";
			reg = <0x00 0x5090000 0x00 0x9000>;
			clock-names = "bi_tcxo", "gcc_gpu_gpll0_clk_src", "gcc_gpu_gpll0_div_clk_src";
			status = "okay";
			#clock-cells = <0x01>;
			#reset-cells = <0x01>;
		};

		interconnect@1705000 {
			phandle = <0x47>;
			compatible = "qcom,sc7180-aggre2-noc";
			reg = <0x00 0x1705000 0x00 0x9000>;
			#interconnect-cells = <0x02>;
			qcom,bcm-voters = <0x5b>;
		};

		spi@88dc000 {
			operating-points-v2 = <0x92>;
			iommus = <0x25 0x20 0x00>;
			interconnect-names = "qspi-config";
			clocks = <0x24 0x35 0x24 0x36>;
			compatible = "qcom,sc7180-qspi", "qcom,qspi-v1";
			reg = <0x00 0x88dc000 0x00 0x600>;
			clock-names = "iface", "core";
			interrupts = <0x00 0x77 0x04>;
			status = "disabled";
			#address-cells = <0x01>;
			#size-cells = <0x00>;
			power-domains = <0x23 0x00>;
			interconnects = <0x28 0x00 0x00 0x29 0x25 0x00>;
		};
	};
};
